AUTOSAR XML (schema 4-2-1)
package /RootP_IntDcm
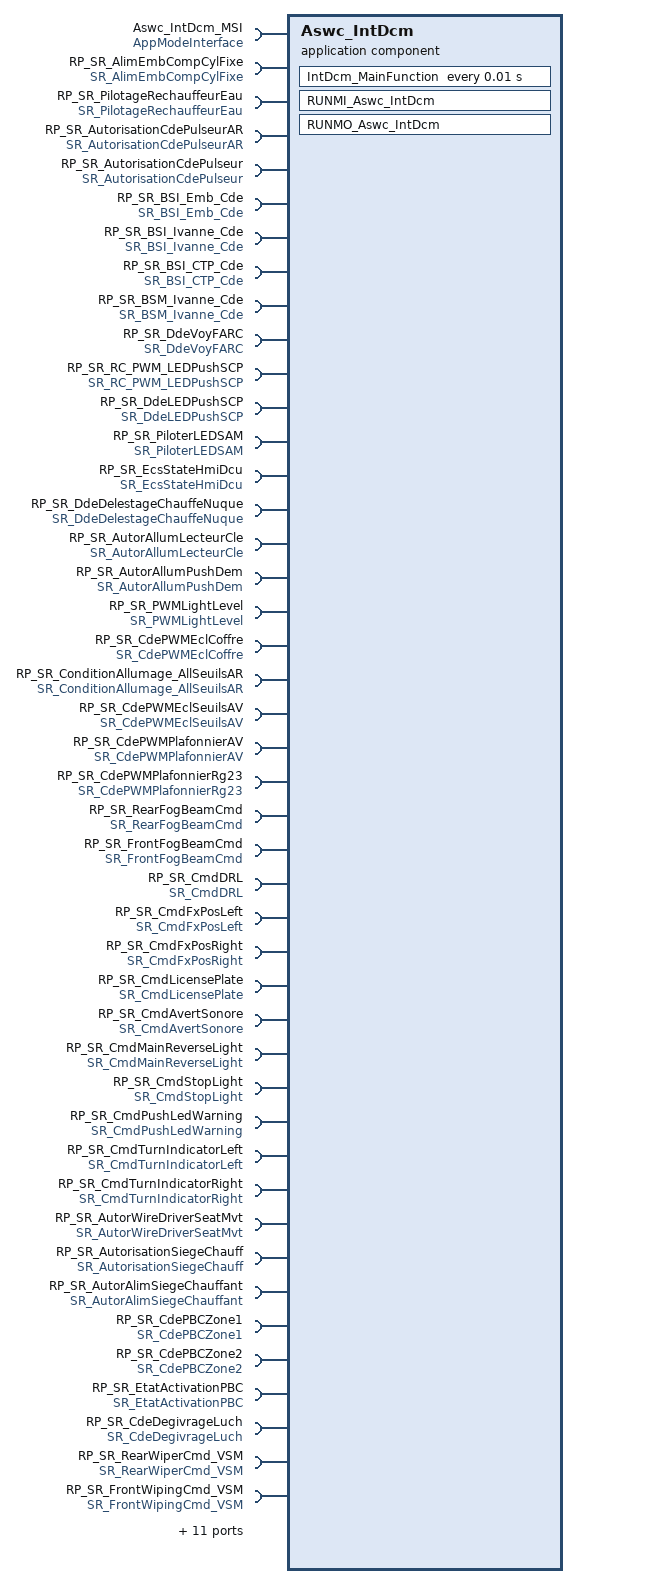
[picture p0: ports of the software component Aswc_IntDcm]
  application sw component type Aswc_IntDcm
    55 x require port:
      Aswc_IntDcm_MSI: required-interface=AppModeInterface
      RP_SR_AlimEmbCompCylFixe: nonqueued-receiver-com-spec{data-element=AlimEmbCompCylFixe, enable-update=0, handle-data-status=0, handle-never-received=0, init-value=CONST_AlimEmbCompCylFixe_0:0}, required-interface=SR_AlimEmbCompCylFixe
      RP_SR_PilotageRechauffeurEau: nonqueued-receiver-com-spec{data-element=PilotageRechauffeurEau, enable-update=0, handle-data-status=0, handle-never-received=0, init-value=CONST_PilotageRechauffeurEau_0:0}, required-interface=SR_PilotageRechauffeurEau
      RP_SR_AutorisationCdePulseurAR: nonqueued-receiver-com-spec{data-element=AutorisationCdePulseurAR, enable-update=0, handle-data-status=0, handle-never-received=0, init-value=CONST_AutorisationCdePulseurAR_0:0}, required-interface=SR_AutorisationCdePulseurAR
      RP_SR_AutorisationCdePulseur: nonqueued-receiver-com-spec{data-element=AutorisationCdePulseur, enable-update=0, handle-data-status=0, handle-never-received=0, init-value=CONST_AutorisationCdePulseur_0:0}, required-interface=SR_AutorisationCdePulseur
      RP_SR_BSI_Emb_Cde: nonqueued-receiver-com-spec{data-element=BSI_Emb_Cde, enable-update=0, handle-data-status=0, handle-never-received=0, init-value=CONST_BSI_Emb_Cde_0:0}, required-interface=SR_BSI_Emb_Cde
      RP_SR_BSI_Ivanne_Cde: nonqueued-receiver-com-spec{data-element=BSI_Ivanne_Cde, enable-update=0, handle-data-status=0, handle-never-received=0, init-value=CONST_BSI_Ivanne_Cde_0:0}, required-interface=SR_BSI_Ivanne_Cde
      RP_SR_BSI_CTP_Cde: nonqueued-receiver-com-spec{data-element=BSI_CTP_Cde, enable-update=0, handle-data-status=0, handle-never-received=0, init-value=CONST_BSI_CTP_Cde_0:0}, required-interface=SR_BSI_CTP_Cde
      RP_SR_BSM_Ivanne_Cde: nonqueued-receiver-com-spec{data-element=BSM_Ivanne_Cde, enable-update=0, handle-data-status=0, handle-never-received=0, init-value=CONST_BSM_Ivanne_Cde_0:0}, required-interface=SR_BSM_Ivanne_Cde
      RP_SR_DdeVoyFARC: nonqueued-receiver-com-spec{data-element=DdeVoyFARC, enable-update=0, handle-data-status=0, handle-never-received=0, init-value=CONST_DdeVoyFARC_0:0}, required-interface=SR_DdeVoyFARC
      RP_SR_RC_PWM_LEDPushSCP: nonqueued-receiver-com-spec{data-element=RC_PWM_LEDPushSCP, enable-update=0, handle-data-status=0, handle-never-received=0, init-value=CONST_RC_PWM_LEDPushSCP_0:0}, required-interface=SR_RC_PWM_LEDPushSCP
      RP_SR_DdeLEDPushSCP: nonqueued-receiver-com-spec{data-element=DdeLEDPushSCP, enable-update=0, handle-data-status=0, handle-never-received=0, init-value=CONST_DdeLEDPushSCP_0:0}, required-interface=SR_DdeLEDPushSCP
      RP_SR_PiloterLEDSAM: nonqueued-receiver-com-spec{data-element=PiloterLEDSAM, enable-update=0, handle-data-status=0, handle-never-received=0, init-value=CONST_PiloterLEDSAM_0:0}, required-interface=SR_PiloterLEDSAM
      RP_SR_EcsStateHmiDcu: nonqueued-receiver-com-spec{data-element=EcsStateHmiDcu, enable-update=0, handle-data-status=0, handle-never-received=0, init-value=CONST_EcsStateHmiDcu_0:0}, required-interface=SR_EcsStateHmiDcu
      RP_SR_DdeDelestageChauffeNuque: nonqueued-receiver-com-spec{data-element=DdeDelestageChauffeNuque, enable-update=0, handle-data-status=0, handle-never-received=0, init-value=CONST_DdeDelestageChauffeNuque_0:0}, required-interface=SR_DdeDelestageChauffeNuque
      RP_SR_AutorAllumLecteurCle: nonqueued-receiver-com-spec{data-element=AutorAllumLecteurCle, enable-update=0, handle-data-status=0, handle-never-received=0, init-value=CONST_AutorAllumLecteurCle_0:0}, required-interface=SR_AutorAllumLecteurCle
      RP_SR_AutorAllumPushDem: nonqueued-receiver-com-spec{data-element=AutorAllumPushDem, enable-update=0, handle-data-status=0, handle-never-received=0, init-value=CONST_AutorAllumPushDem_0:0}, required-interface=SR_AutorAllumPushDem
      RP_SR_PWMLightLevel: nonqueued-receiver-com-spec{data-element=PWMLightLevel, enable-update=0, handle-data-status=0, handle-never-received=0, init-value=CONST_PWMLightLevel_0:0}, required-interface=SR_PWMLightLevel
      RP_SR_CdePWMEclCoffre: nonqueued-receiver-com-spec{data-element=CdePWMEclCoffre, enable-update=0, handle-data-status=0, handle-never-received=0, init-value=CONST_CdePWMEclCoffre_0:0}, required-interface=SR_CdePWMEclCoffre
      RP_SR_ConditionAllumage_AllSeuilsAR: nonqueued-receiver-com-spec{data-element=ConditionAllumage_AllSeuilsAR, enable-update=0, handle-data-status=0, handle-never-received=0, init-value=CONST_ConditionAllumage_AllSeuilsAR_0:0}, required-interface=SR_ConditionAllumage_AllSeuilsAR
      RP_SR_CdePWMEclSeuilsAV: nonqueued-receiver-com-spec{data-element=CdePWMEclSeuilsAV, enable-update=0, handle-data-status=0, handle-never-received=0, init-value=CONST_CdePWMEclSeuilsAV_0:0}, required-interface=SR_CdePWMEclSeuilsAV
      RP_SR_CdePWMPlafonnierAV: nonqueued-receiver-com-spec{data-element=CdePWMPlafonnierAV, enable-update=0, handle-data-status=0, handle-never-received=0, init-value=CONST_CdePWMPlafonnierAV_0:0}, required-interface=SR_CdePWMPlafonnierAV
      RP_SR_CdePWMPlafonnierRg23: nonqueued-receiver-com-spec{data-element=CdePWMPlafonnierRg23, enable-update=0, handle-data-status=0, handle-never-received=0, init-value=CONST_CdePWMPlafonnierRg23_0:0}, required-interface=SR_CdePWMPlafonnierRg23
      RP_SR_RearFogBeamCmd: nonqueued-receiver-com-spec{data-element=RearFogBeamCmd, enable-update=0, handle-data-status=0, handle-never-received=0, init-value=CONST_RearFogBeamCmd_0:0}, required-interface=SR_RearFogBeamCmd
      RP_SR_FrontFogBeamCmd: nonqueued-receiver-com-spec{data-element=FrontFogBeamCmd, enable-update=0, handle-data-status=0, handle-never-received=0, init-value=CONST_FrontFogBeamCmd_0:0}, required-interface=SR_FrontFogBeamCmd
      RP_SR_CmdDRL: nonqueued-receiver-com-spec{data-element=CmdDRL, enable-update=0, handle-data-status=0, handle-never-received=0, init-value=CONST_CmdDRL_0:0}, required-interface=SR_CmdDRL
      RP_SR_CmdFxPosLeft: nonqueued-receiver-com-spec{data-element=CmdFxPosLeft, enable-update=0, handle-data-status=0, handle-never-received=0, init-value=CONST_CmdFxPosLeft_0:0}, required-interface=SR_CmdFxPosLeft
      RP_SR_CmdFxPosRight: nonqueued-receiver-com-spec{data-element=CmdFxPosRight, enable-update=0, handle-data-status=0, handle-never-received=0, init-value=CONST_CmdFxPosRight_0:0}, required-interface=SR_CmdFxPosRight
      RP_SR_CmdLicensePlate: nonqueued-receiver-com-spec{data-element=CmdLicensePlate, enable-update=0, handle-data-status=0, handle-never-received=0, init-value=CONST_CmdLicensePlate_0:0}, required-interface=SR_CmdLicensePlate
      RP_SR_CmdAvertSonore: nonqueued-receiver-com-spec{data-element=CmdAvertSonore, enable-update=0, handle-data-status=0, handle-never-received=0, init-value=CONST_CmdAvertSonore_0:0}, required-interface=SR_CmdAvertSonore
      RP_SR_CmdMainReverseLight: nonqueued-receiver-com-spec{data-element=CmdMainReverseLight, enable-update=0, handle-data-status=0, handle-never-received=0, init-value=CONST_CmdMainReverseLight_0:0}, required-interface=SR_CmdMainReverseLight
      RP_SR_CmdStopLight: nonqueued-receiver-com-spec{data-element=CmdStopLight, enable-update=0, handle-data-status=0, handle-never-received=0, init-value=CONST_CmdStopLight_0:0}, required-interface=SR_CmdStopLight
      RP_SR_CmdPushLedWarning: nonqueued-receiver-com-spec{data-element=CmdPushLedWarning, enable-update=0, handle-data-status=0, handle-never-received=0, init-value=CONST_CmdPushLedWarning_0:0}, required-interface=SR_CmdPushLedWarning
      RP_SR_CmdTurnIndicatorLeft: nonqueued-receiver-com-spec{data-element=CmdTurnIndicatorLeft, enable-update=0, handle-data-status=0, handle-never-received=0, init-value=CONST_CmdTurnIndicatorLeft_0:0}, required-interface=SR_CmdTurnIndicatorLeft
      RP_SR_CmdTurnIndicatorRight: nonqueued-receiver-com-spec{data-element=CmdTurnIndicatorRight, enable-update=0, handle-data-status=0, handle-never-received=0, init-value=CONST_CmdTurnIndicatorRight_0:0}, required-interface=SR_CmdTurnIndicatorRight
      RP_SR_AutorWireDriverSeatMvt: nonqueued-receiver-com-spec{data-element=AutorWireDriverSeatMvt, enable-update=0, handle-data-status=0, handle-never-received=0, init-value=CONST_AutorWireDriverSeatMvt_0:0}, required-interface=SR_AutorWireDriverSeatMvt
      RP_SR_AutorisationSiegeChauff: nonqueued-receiver-com-spec{data-element=AutorisationSiegeChauff, enable-update=0, handle-data-status=0, handle-never-received=0, init-value=CONST_AutorisationSiegeChauff_0:0}, required-interface=SR_AutorisationSiegeChauff
      RP_SR_AutorAlimSiegeChauffant: nonqueued-receiver-com-spec{data-element=AutorAlimSiegeChauffant, enable-update=0, handle-data-status=0, handle-never-received=0, init-value=CONST_AutorAlimSiegeChauffant_0:0}, required-interface=SR_AutorAlimSiegeChauffant
      RP_SR_CdePBCZone1: nonqueued-receiver-com-spec{data-element=CdePBCZone1, enable-update=0, handle-data-status=0, handle-never-received=0, init-value=CONST_CdePBCZone1_0:0}, required-interface=SR_CdePBCZone1
      RP_SR_CdePBCZone2: nonqueued-receiver-com-spec{data-element=CdePBCZone2, enable-update=0, handle-data-status=0, handle-never-received=0, init-value=CONST_CdePBCZone2_0:0}, required-interface=SR_CdePBCZone2
      RP_SR_EtatActivationPBC: nonqueued-receiver-com-spec{data-element=EtatActivationPBC, enable-update=0, handle-data-status=0, handle-never-received=0, init-value=CONST_EtatActivationPBC_0:0}, required-interface=SR_EtatActivationPBC
      RP_SR_CdeDegivrageLuch: nonqueued-receiver-com-spec{data-element=CdeDegivrageLuch, enable-update=0, handle-data-status=0, handle-never-received=0, init-value=CONST_CdeDegivrageLuch_0:0}, required-interface=SR_CdeDegivrageLuch
      RP_SR_RearWiperCmd_VSM: nonqueued-receiver-com-spec{data-element=RearWipingCommand, enable-update=0, handle-data-status=0, handle-never-received=0, init-value=CONST_RearWipingCommand_0:105}, required-interface=SR_RearWiperCmd_VSM
      RP_SR_FrontWipingCmd_VSM: nonqueued-receiver-com-spec{data-element=FrontWipingCommand, enable-update=0, handle-data-status=0, handle-never-received=0, init-value=CONST_FrontWipingCommand_0:105}, required-interface=SR_FrontWipingCmd_VSM
      RP_SR_RearWashingCmd_VSM: nonqueued-receiver-com-spec{data-element=RearWashingCommand, enable-update=0, handle-data-status=0, handle-never-received=0, init-value=CONST_RearWashingCommand_0:0}, required-interface=SR_RearWashingCmd_VSM
      RP_SR_FrontWashingCmd_VSM: nonqueued-receiver-com-spec{data-element=FrontWashingCommand, enable-update=0, handle-data-status=0, handle-never-received=0, init-value=CONST_FrontWashingCommand_0:0}, required-interface=SR_FrontWashingCmd_VSM
      RP_SR_AffMenuEclAmbi: nonqueued-receiver-com-spec{data-element=AffMenuEclAmbi, enable-update=0, handle-data-status=0, handle-never-received=0, init-value=CONST_AffMenuEclAmbi_0:0}, required-interface=SR_AffMenuEclAmbi
      RP_SR_CdeAlerteSonoreKlaxon: nonqueued-receiver-com-spec{data-element=CdeAlerteSonoreKlaxon, enable-update=0, handle-data-status=0, handle-never-received=0, init-value=CONST_CdeAlerteSonoreKlaxon_0:0}, required-interface=SR_CdeAlerteSonoreKlaxon
      RP_SR_CmdActivationSurvAS: nonqueued-receiver-com-spec{data-element=CmdActivationSurvAS, enable-update=0, handle-data-status=0, handle-never-received=0, init-value=CONST_CmdActivationSurvAS_0:4}, required-interface=SR_CmdActivationSurvAS
      RP_SR_CmdActivationSurvSIR: nonqueued-receiver-com-spec{data-element=CmdActivationSurvSIR, enable-update=0, handle-data-status=0, handle-never-received=0, init-value=CONST_CmdActivationSurvSIR_0:0}, required-interface=SR_CmdActivationSurvSIR
      RP_SR_CmdActivationSurvVOL: nonqueued-receiver-com-spec{data-element=CmdActivationSurvVOL, enable-update=0, handle-data-status=0, handle-never-received=0, init-value=CONST_CmdActivationSurvVOL_0:4}, required-interface=SR_CmdActivationSurvVOL
      RP_SR_DdeSignalEffractionInterne: nonqueued-receiver-com-spec{data-element=DdeSignalEffractionInterne, enable-update=0, handle-data-status=0, handle-never-received=0, init-value=CONST_DdeSignalEffractionInterne_0:0}, required-interface=SR_DdeSignalEffractionInterne
      RP_SR_SAV_RC_LEDPushAlarme: nonqueued-receiver-com-spec{data-element=SAV_RC_LEDPushAlarme, enable-update=0, handle-data-status=0, handle-never-received=0, init-value=CONST_SAV_RC_LEDPushAlarme_0:0}, required-interface=SR_SAV_RC_LEDPushAlarme
      RP_SR_SignalActivAlarmeInterne: nonqueued-receiver-com-spec{data-element=SignalActivAlarmeInterne, enable-update=0, handle-data-status=0, handle-never-received=0, init-value=CONST_SignalActivAlarmeInterne_0:0}, required-interface=SR_SignalActivAlarmeInterne
      RP_SR_SignalDesactivAlarmeInterne: nonqueued-receiver-com-spec{data-element=SignalDesactivAlarmeInterne, enable-update=0, handle-data-status=0, handle-never-received=0, init-value=CONST_SignalDesactivAlarmeInterne_0:0}, required-interface=SR_SignalDesactivAlarmeInterne
    54 x provide/require port:
      PRP_SR_AlimEmbCompCylFixe_IoFromDcm: nonqueued-receiver-com-spec{data-element=AlimEmbCompCylFixe, enable-update=0, handle-data-status=0, handle-never-received=0, init-value=CONST_AlimEmbCompCylFixe_0:0}, provided-required-interface=SR_AlimEmbCompCylFixe_IoFromDcm
      PRP_SR_PilotageRechauffeurEau_IoFromDcm: nonqueued-receiver-com-spec{data-element=PilotageRechauffeurEau, enable-update=0, handle-data-status=0, handle-never-received=0, init-value=CONST_PilotageRechauffeurEau_0:0}, provided-required-interface=SR_PilotageRechauffeurEau_IoFromDcm
      PRP_SR_AutorisationCdePulseurAR_IoFromDcm: nonqueued-receiver-com-spec{data-element=AutorisationCdePulseurAR, enable-update=0, handle-data-status=0, handle-never-received=0, init-value=CONST_AutorisationCdePulseurAR_0:0}, provided-required-interface=SR_AutorisationCdePulseurAR_IoFromDcm
      PRP_SR_AutorisationCdePulseur_IoFromDcm: nonqueued-receiver-com-spec{data-element=AutorisationCdePulseur, enable-update=0, handle-data-status=0, handle-never-received=0, init-value=CONST_AutorisationCdePulseur_0:0}, provided-required-interface=SR_AutorisationCdePulseur_IoFromDcm
      PRP_SR_BSI_Emb_Cde_IoFromDcm: nonqueued-receiver-com-spec{data-element=BSI_Emb_Cde, enable-update=0, handle-data-status=0, handle-never-received=0, init-value=CONST_BSI_Emb_Cde_0:0}, provided-required-interface=SR_BSI_Emb_Cde_IoFromDcm
      PRP_SR_BSI_Ivanne_Cde_IoFromDcm: nonqueued-receiver-com-spec{data-element=BSI_Ivanne_Cde, enable-update=0, handle-data-status=0, handle-never-received=0, init-value=CONST_BSI_Ivanne_Cde_0:0}, provided-required-interface=SR_BSI_Ivanne_Cde_IoFromDcm
      PRP_SR_BSI_CTP_Cde_IoFromDcm: nonqueued-receiver-com-spec{data-element=BSI_CTP_Cde, enable-update=0, handle-data-status=0, handle-never-received=0, init-value=CONST_BSI_CTP_Cde_0:0}, provided-required-interface=SR_BSI_CTP_Cde_IoFromDcm
      PRP_SR_BSM_Ivanne_Cde_IoFromDcm: nonqueued-receiver-com-spec{data-element=BSM_Ivanne_Cde, enable-update=0, handle-data-status=0, handle-never-received=0, init-value=CONST_BSM_Ivanne_Cde_0:0}, provided-required-interface=SR_BSM_Ivanne_Cde_IoFromDcm
      PRP_SR_DdeVoyFARC_IoFromDcm: nonqueued-receiver-com-spec{data-element=DdeVoyFARC, enable-update=0, handle-data-status=0, handle-never-received=0, init-value=CONST_DdeVoyFARC_0:0}, provided-required-interface=SR_DdeVoyFARC_IoFromDcm
      PRP_SR_RC_PWM_LEDPushSCP_IoFromDcm: nonqueued-receiver-com-spec{data-element=RC_PWM_LEDPushSCP, enable-update=0, handle-data-status=0, handle-never-received=0, init-value=CONST_RC_PWM_LEDPushSCP_0:0}, provided-required-interface=SR_RC_PWM_LEDPushSCP_IoFromDcm
      PRP_SR_DdeLEDPushSCP_IoFromDcm: nonqueued-receiver-com-spec{data-element=DdeLEDPushSCP, enable-update=0, handle-data-status=0, handle-never-received=0, init-value=CONST_DdeLEDPushSCP_0:0}, provided-required-interface=SR_DdeLEDPushSCP_IoFromDcm
      PRP_SR_PiloterLEDSAM_IoFromDcm: nonqueued-receiver-com-spec{data-element=PiloterLEDSAM, enable-update=0, handle-data-status=0, handle-never-received=0, init-value=CONST_PiloterLEDSAM_0:0}, provided-required-interface=SR_PiloterLEDSAM_IoFromDcm
      PRP_SR_EcsStateHmiDcu_IoFromDcm: nonqueued-receiver-com-spec{data-element=EcsStateHmiDcu, enable-update=0, handle-data-status=0, handle-never-received=0, init-value=CONST_EcsStateHmiDcu_0:0}, provided-required-interface=SR_EcsStateHmiDcu_IoFromDcm
      PRP_SR_DdeDelestageChauffeNuque_IoFromDcm: nonqueued-receiver-com-spec{data-element=DdeDelestageChauffeNuque, enable-update=0, handle-data-status=0, handle-never-received=0, init-value=CONST_DdeDelestageChauffeNuque_0:0}, provided-required-interface=SR_DdeDelestageChauffeNuque_IoFromDcm
      PRP_SR_AutorAllumLecteurCle_IoFromDcm: nonqueued-receiver-com-spec{data-element=AutorAllumLecteurCle, enable-update=0, handle-data-status=0, handle-never-received=0, init-value=CONST_AutorAllumLecteurCle_0:0}, provided-required-interface=SR_AutorAllumLecteurCle_IoFromDcm
      PRP_SR_AutorAllumPushDem_IoFromDcm: nonqueued-receiver-com-spec{data-element=AutorAllumPushDem, enable-update=0, handle-data-status=0, handle-never-received=0, init-value=CONST_AutorAllumPushDem_0:0}, provided-required-interface=SR_AutorAllumPushDem_IoFromDcm
      PRP_SR_PWMLightLevel_IoFromDcm: nonqueued-receiver-com-spec{data-element=PWMLightLevel, enable-update=0, handle-data-status=0, handle-never-received=0, init-value=CONST_PWMLightLevel_0:0}, provided-required-interface=SR_PWMLightLevel_IoFromDcm
      PRP_SR_CdePWMEclCoffre_IoFromDcm: nonqueued-receiver-com-spec{data-element=CdePWMEclCoffre, enable-update=0, handle-data-status=0, handle-never-received=0, init-value=CONST_CdePWMEclCoffre_0:0}, provided-required-interface=SR_CdePWMEclCoffre_IoFromDcm
      PRP_SR_ConditionAllumage_AllSeuilsAR_IoFromDcm: nonqueued-receiver-com-spec{data-element=ConditionAllumage_AllSeuilsAR, enable-update=0, handle-data-status=0, handle-never-received=0, init-value=CONST_ConditionAllumage_AllSeuilsAR_0:0}, provided-required-interface=SR_ConditionAllumage_AllSeuilsAR_IoFromDcm
      PRP_SR_CdePWMEclSeuilsAV_IoFromDcm: nonqueued-receiver-com-spec{data-element=CdePWMEclSeuilsAV, enable-update=0, handle-data-status=0, handle-never-received=0, init-value=CONST_CdePWMEclSeuilsAV_0:0}, provided-required-interface=SR_CdePWMEclSeuilsAV_IoFromDcm
      PRP_SR_CdePWMPlafonnierAV_IoFromDcm: nonqueued-receiver-com-spec{data-element=CdePWMPlafonnierAV, enable-update=0, handle-data-status=0, handle-never-received=0, init-value=CONST_CdePWMPlafonnierAV_0:0}, provided-required-interface=SR_CdePWMPlafonnierAV_IoFromDcm
      PRP_SR_CdePWMPlafonnierRg23_IoFromDcm: nonqueued-receiver-com-spec{data-element=CdePWMPlafonnierRg23, enable-update=0, handle-data-status=0, handle-never-received=0, init-value=CONST_CdePWMPlafonnierRg23_0:0}, provided-required-interface=SR_CdePWMPlafonnierRg23_IoFromDcm
      PRP_SR_RearFogBeamCmd_IoFromDcm: nonqueued-receiver-com-spec{data-element=RearFogBeamCmd, enable-update=0, handle-data-status=0, handle-never-received=0, init-value=CONST_RearFogBeamCmd_0:0}, provided-required-interface=SR_RearFogBeamCmd_IoFromDcm
      PRP_SR_FrontFogBeamCmd_IoFromDcm: nonqueued-receiver-com-spec{data-element=FrontFogBeamCmd, enable-update=0, handle-data-status=0, handle-never-received=0, init-value=CONST_FrontFogBeamCmd_0:0}, provided-required-interface=SR_FrontFogBeamCmd_IoFromDcm
      PRP_SR_CmdDRL_IoFromDcm: nonqueued-receiver-com-spec{data-element=CmdDRL, enable-update=0, handle-data-status=0, handle-never-received=0, init-value=CONST_CmdDRL_0:0}, provided-required-interface=SR_CmdDRL_IoFromDcm
      PRP_SR_CmdFxPosLeft_IoFromDcm: nonqueued-receiver-com-spec{data-element=CmdFxPosLeft, enable-update=0, handle-data-status=0, handle-never-received=0, init-value=CONST_CmdFxPosLeft_0:0}, provided-required-interface=SR_CmdFxPosLeft_IoFromDcm
      PRP_SR_CmdFxPosRight_IoFromDcm: nonqueued-receiver-com-spec{data-element=CmdFxPosRight, enable-update=0, handle-data-status=0, handle-never-received=0, init-value=CONST_CmdFxPosRight_0:0}, provided-required-interface=SR_CmdFxPosRight_IoFromDcm
      PRP_SR_CmdLicensePlate_IoFromDcm: nonqueued-receiver-com-spec{data-element=CmdLicensePlate, enable-update=0, handle-data-status=0, handle-never-received=0, init-value=CONST_CmdLicensePlate_0:0}, provided-required-interface=SR_CmdLicensePlate_IoFromDcm
      PRP_SR_CmdAvertSonore_IoFromDcm: nonqueued-receiver-com-spec{data-element=CmdAvertSonore, enable-update=0, handle-data-status=0, handle-never-received=0, init-value=CONST_CmdAvertSonore_0:0}, provided-required-interface=SR_CmdAvertSonore_IoFromDcm
      PRP_SR_CmdMainReverseLight_IoFromDcm: nonqueued-receiver-com-spec{data-element=CmdMainReverseLight, enable-update=0, handle-data-status=0, handle-never-received=0, init-value=CONST_CmdMainReverseLight_0:0}, provided-required-interface=SR_CmdMainReverseLight_IoFromDcm
      PRP_SR_CmdStopLight_IoFromDcm: nonqueued-receiver-com-spec{data-element=CmdStopLight, enable-update=0, handle-data-status=0, handle-never-received=0, init-value=CONST_CmdStopLight_0:0}, provided-required-interface=SR_CmdStopLight_IoFromDcm
      PRP_SR_CmdPushLedWarning_IoFromDcm: nonqueued-receiver-com-spec{data-element=CmdPushLedWarning, enable-update=0, handle-data-status=0, handle-never-received=0, init-value=CONST_CmdPushLedWarning_0:0}, provided-required-interface=SR_CmdPushLedWarning_IoFromDcm
      PRP_SR_CmdTurnIndicatorLeft_IoFromDcm: nonqueued-receiver-com-spec{data-element=CmdTurnIndicatorLeft, enable-update=0, handle-data-status=0, handle-never-received=0, init-value=CONST_CmdTurnIndicatorLeft_0:0}, provided-required-interface=SR_CmdTurnIndicatorLeft_IoFromDcm
      PRP_SR_CmdTurnIndicatorRight_IoFromDcm: nonqueued-receiver-com-spec{data-element=CmdTurnIndicatorRight, enable-update=0, handle-data-status=0, handle-never-received=0, init-value=CONST_CmdTurnIndicatorRight_0:0}, provided-required-interface=SR_CmdTurnIndicatorRight_IoFromDcm
      PRP_SR_AutorWireDriverSeatMvt_IoFromDcm: nonqueued-receiver-com-spec{data-element=AutorWireDriverSeatMvt, enable-update=0, handle-data-status=0, handle-never-received=0, init-value=CONST_AutorWireDriverSeatMvt_0:0}, provided-required-interface=SR_AutorWireDriverSeatMvt_IoFromDcm
      PRP_SR_AutorisationSiegeChauff_IoFromDcm: nonqueued-receiver-com-spec{data-element=AutorisationSiegeChauff, enable-update=0, handle-data-status=0, handle-never-received=0, init-value=CONST_AutorisationSiegeChauff_0:0}, provided-required-interface=SR_AutorisationSiegeChauff_IoFromDcm
      PRP_SR_AutorAlimSiegeChauffant_IoFromDcm: nonqueued-receiver-com-spec{data-element=AutorAlimSiegeChauffant, enable-update=0, handle-data-status=0, handle-never-received=0, init-value=CONST_AutorAlimSiegeChauffant_0:0}, provided-required-interface=SR_AutorAlimSiegeChauffant_IoFromDcm
      PRP_SR_CdePBCZone1_IoFromDcm: nonqueued-receiver-com-spec{data-element=CdePBCZone1, enable-update=0, handle-data-status=0, handle-never-received=0, init-value=CONST_CdePBCZone1_0:0}, provided-required-interface=SR_CdePBCZone1_IoFromDcm
      PRP_SR_CdePBCZone2_IoFromDcm: nonqueued-receiver-com-spec{data-element=CdePBCZone2, enable-update=0, handle-data-status=0, handle-never-received=0, init-value=CONST_CdePBCZone2_0:0}, provided-required-interface=SR_CdePBCZone2_IoFromDcm
      PRP_SR_EtatActivationPBC_IoFromDcm: nonqueued-receiver-com-spec{data-element=EtatActivationPBC, enable-update=0, handle-data-status=0, handle-never-received=0, init-value=CONST_EtatActivationPBC_0:0}, provided-required-interface=SR_EtatActivationPBC_IoFromDcm
      PRP_SR_CdeDegivrageLuch_IoFromDcm: nonqueued-receiver-com-spec{data-element=CdeDegivrageLuch, enable-update=0, handle-data-status=0, handle-never-received=0, init-value=CONST_CdeDegivrageLuch_0:0}, provided-required-interface=SR_CdeDegivrageLuch_IoFromDcm
      PRP_SR_RearWiperCmd_VSM_IoFromDcm: nonqueued-receiver-com-spec{data-element=RearWipingCommand, enable-update=0, handle-data-status=0, handle-never-received=0, init-value=CONST_RearWipingCommand_0:105}, provided-required-interface=SR_RearWiperCmd_VSM_IoFromDcm
      PRP_SR_FrontWipingCmd_VSM_IoFromDcm: nonqueued-receiver-com-spec{data-element=FrontWipingCommand, enable-update=0, handle-data-status=0, handle-never-received=0, init-value=CONST_FrontWipingCommand_0:105}, provided-required-interface=SR_FrontWipingCmd_VSM_IoFromDcm
      PRP_SR_RearWashingCmd_VSM_IoFromDcm: nonqueued-receiver-com-spec{data-element=RearWashingCommand, enable-update=0, handle-data-status=0, handle-never-received=0, init-value=CONST_RearWashingCommand_0:0}, provided-required-interface=SR_RearWashingCmd_VSM_IoFromDcm
      PRP_SR_FrontWashingCmd_VSM_IoFromDcm: nonqueued-receiver-com-spec{data-element=FrontWashingCommand, enable-update=0, handle-data-status=0, handle-never-received=0, init-value=CONST_FrontWashingCommand_0:0}, provided-required-interface=SR_FrontWashingCmd_VSM_IoFromDcm
      PRP_SR_AffMenuEclAmbi_IoFromDcm: nonqueued-receiver-com-spec{data-element=AffMenuEclAmbi, enable-update=0, handle-data-status=0, handle-never-received=0, init-value=CONST_AffMenuEclAmbi_0:0}, provided-required-interface=SR_AffMenuEclAmbi_IoFromDcm
      PRP_SR_CdeAlerteSonoreKlaxon_IoFromDcm: nonqueued-receiver-com-spec{data-element=CdeAlerteSonoreKlaxon, enable-update=0, handle-data-status=0, handle-never-received=0, init-value=CONST_CdeAlerteSonoreKlaxon_0:0}, provided-required-interface=SR_CdeAlerteSonoreKlaxon_IoFromDcm
      PRP_SR_CmdActivationSurvAS_IoFromDcm: nonqueued-receiver-com-spec{data-element=CmdActivationSurvAS, enable-update=0, handle-data-status=0, handle-never-received=0, init-value=CONST_CmdActivationSurvAS_0:4}, provided-required-interface=SR_CmdActivationSurvAS_IoFromDcm
      PRP_SR_CmdActivationSurvSIR_IoFromDcm: nonqueued-receiver-com-spec{data-element=CmdActivationSurvSIR, enable-update=0, handle-data-status=0, handle-never-received=0, init-value=CONST_CmdActivationSurvSIR_0:0}, provided-required-interface=SR_CmdActivationSurvSIR_IoFromDcm
      PRP_SR_CmdActivationSurvVOL_IoFromDcm: nonqueued-receiver-com-spec{data-element=CmdActivationSurvVOL, enable-update=0, handle-data-status=0, handle-never-received=0, init-value=CONST_CmdActivationSurvVOL_0:4}, provided-required-interface=SR_CmdActivationSurvVOL_IoFromDcm
      PRP_SR_DdeSignalEffractionInterne_IoFromDcm: nonqueued-receiver-com-spec{data-element=DdeSignalEffractionInterne, enable-update=0, handle-data-status=0, handle-never-received=0, init-value=CONST_DdeSignalEffractionInterne_0:0}, provided-required-interface=SR_DdeSignalEffractionInterne_IoFromDcm
      PRP_SR_SAV_RC_LEDPushAlarme_IoFromDcm: nonqueued-receiver-com-spec{data-element=SAV_RC_LEDPushAlarme, enable-update=0, handle-data-status=0, handle-never-received=0, init-value=CONST_SAV_RC_LEDPushAlarme_0:0}, provided-required-interface=SR_SAV_RC_LEDPushAlarme_IoFromDcm
      PRP_SR_SignalActivAlarmeInterne_IoFromDcm: nonqueued-receiver-com-spec{data-element=SignalActivAlarmeInterne, enable-update=0, handle-data-status=0, handle-never-received=0, init-value=CONST_SignalActivAlarmeInterne_0:0}, provided-required-interface=SR_SignalActivAlarmeInterne_IoFromDcm
      PRP_SR_SignalDesactivAlarmeInterne_IoFromDcm: nonqueued-receiver-com-spec{data-element=SignalDesactivAlarmeInterne, enable-update=0, handle-data-status=0, handle-never-received=0, init-value=CONST_SignalDesactivAlarmeInterne_0:0}, provided-required-interface=SR_SignalDesactivAlarmeInterne_IoFromDcm
    behavior IB_Aswc_IntDcm: data-type-mapping=ApplicationModeMapping, handle-termination-and-restart=NO-SUPPORT
      timing event IntDcm_MainFunction_Cyclic: start-on-event=IntDcm_MainFunction, period=0.01
        disabled-mode:
          Aswc_IntDcm_MSI.AppMode.APP_WAKEUP
          Aswc_IntDcm_MSI.AppMode.APP_OFF
          Aswc_IntDcm_MSI.AppMode.APP_SYNC_INIT1
          Aswc_IntDcm_MSI.AppMode.APP_SYNC_INIT2
          Aswc_IntDcm_MSI.AppMode.APP_CONFIG
      swc mode switch event RUNMI_Aswc_IntDcm_NvmIn: start-on-event=RUNMI_Aswc_IntDcm, activation=ON-ENTRY, mode=Aswc_IntDcm_MSI.AppMode.APP_SYNC_INIT1
      swc mode switch event RUNMO_Aswc_IntDcm_NvmOut: start-on-event=RUNMO_Aswc_IntDcm, activation=ON-ENTRY, mode=Aswc_IntDcm_MSI.AppMode.APP_ON
      runnable IntDcm_MainFunction
        data-read-access:
          54 x access:
            Dra_SR_AlimEmbCompCylFixe: accessed-variable=RP_SR_AlimEmbCompCylFixe.AlimEmbCompCylFixe
            Dra_SR_PilotageRechauffeurEau: accessed-variable=RP_SR_PilotageRechauffeurEau.PilotageRechauffeurEau
            Dra_SR_AutorisationCdePulseurAR: accessed-variable=RP_SR_AutorisationCdePulseurAR.AutorisationCdePulseurAR
            Dra_SR_AutorisationCdePulseur: accessed-variable=RP_SR_AutorisationCdePulseur.AutorisationCdePulseur
            Dra_SR_BSI_Emb_Cde: accessed-variable=RP_SR_BSI_Emb_Cde.BSI_Emb_Cde
            Dra_SR_BSI_Ivanne_Cde: accessed-variable=RP_SR_BSI_Ivanne_Cde.BSI_Ivanne_Cde
            Dra_SR_BSI_CTP_Cde: accessed-variable=RP_SR_BSI_CTP_Cde.BSI_CTP_Cde
            Dra_SR_BSM_Ivanne_Cde: accessed-variable=RP_SR_BSM_Ivanne_Cde.BSM_Ivanne_Cde
            Dra_SR_DdeVoyFARC: accessed-variable=RP_SR_DdeVoyFARC.DdeVoyFARC
            Dra_SR_RC_PWM_LEDPushSCP: accessed-variable=RP_SR_RC_PWM_LEDPushSCP.RC_PWM_LEDPushSCP
            Dra_SR_DdeLEDPushSCP: accessed-variable=RP_SR_DdeLEDPushSCP.DdeLEDPushSCP
            Dra_SR_PiloterLEDSAM: accessed-variable=RP_SR_PiloterLEDSAM.PiloterLEDSAM
            Dra_SR_EcsStateHmiDcu: accessed-variable=RP_SR_EcsStateHmiDcu.EcsStateHmiDcu
            Dra_SR_DdeDelestageChauffeNuque: accessed-variable=RP_SR_DdeDelestageChauffeNuque.DdeDelestageChauffeNuque
            Dra_SR_AutorAllumLecteurCle: accessed-variable=RP_SR_AutorAllumLecteurCle.AutorAllumLecteurCle
            Dra_SR_AutorAllumPushDem: accessed-variable=RP_SR_AutorAllumPushDem.AutorAllumPushDem
            Dra_SR_PWMLightLevel: accessed-variable=RP_SR_PWMLightLevel.PWMLightLevel
            Dra_SR_CdePWMEclCoffre: accessed-variable=RP_SR_CdePWMEclCoffre.CdePWMEclCoffre
            Dra_SR_ConditionAllumage_AllSeuilsAR: accessed-variable=RP_SR_ConditionAllumage_AllSeuilsAR.ConditionAllumage_AllSeuilsAR
            Dra_SR_CdePWMEclSeuilsAV: accessed-variable=RP_SR_CdePWMEclSeuilsAV.CdePWMEclSeuilsAV
            Dra_SR_CdePWMPlafonnierAV: accessed-variable=RP_SR_CdePWMPlafonnierAV.CdePWMPlafonnierAV
            Dra_SR_CdePWMPlafonnierRg23: accessed-variable=RP_SR_CdePWMPlafonnierRg23.CdePWMPlafonnierRg23
            Dra_SR_RearFogBeamCmd: accessed-variable=RP_SR_RearFogBeamCmd.RearFogBeamCmd
            Dra_SR_FrontFogBeamCmd: accessed-variable=RP_SR_FrontFogBeamCmd.FrontFogBeamCmd
            Dra_SR_CmdDRL: accessed-variable=RP_SR_CmdDRL.CmdDRL
            Dra_SR_CmdFxPosLeft: accessed-variable=RP_SR_CmdFxPosLeft.CmdFxPosLeft
            Dra_SR_CmdFxPosRight: accessed-variable=RP_SR_CmdFxPosRight.CmdFxPosRight
            Dra_SR_CmdLicensePlate: accessed-variable=RP_SR_CmdLicensePlate.CmdLicensePlate
            Dra_SR_CmdAvertSonore: accessed-variable=RP_SR_CmdAvertSonore.CmdAvertSonore
            Dra_SR_CmdMainReverseLight: accessed-variable=RP_SR_CmdMainReverseLight.CmdMainReverseLight
            Dra_SR_CmdStopLight: accessed-variable=RP_SR_CmdStopLight.CmdStopLight
            Dra_SR_CmdPushLedWarning: accessed-variable=RP_SR_CmdPushLedWarning.CmdPushLedWarning
            Dra_SR_CmdTurnIndicatorLeft: accessed-variable=RP_SR_CmdTurnIndicatorLeft.CmdTurnIndicatorLeft
            Dra_SR_CmdTurnIndicatorRight: accessed-variable=RP_SR_CmdTurnIndicatorRight.CmdTurnIndicatorRight
            Dra_SR_AutorWireDriverSeatMvt: accessed-variable=RP_SR_AutorWireDriverSeatMvt.AutorWireDriverSeatMvt
            Dra_SR_AutorisationSiegeChauff: accessed-variable=RP_SR_AutorisationSiegeChauff.AutorisationSiegeChauff
            Dra_SR_AutorAlimSiegeChauffant: accessed-variable=RP_SR_AutorAlimSiegeChauffant.AutorAlimSiegeChauffant
            Dra_SR_CdePBCZone1: accessed-variable=RP_SR_CdePBCZone1.CdePBCZone1
            Dra_SR_CdePBCZone2: accessed-variable=RP_SR_CdePBCZone2.CdePBCZone2
            Dra_SR_EtatActivationPBC: accessed-variable=RP_SR_EtatActivationPBC.EtatActivationPBC
            Dra_SR_CdeDegivrageLuch: accessed-variable=RP_SR_CdeDegivrageLuch.CdeDegivrageLuch
            Dra_SR_RearWiperCmd_VSM: accessed-variable=RP_SR_RearWiperCmd_VSM.RearWipingCommand
            Dra_SR_FrontWipingCmd_VSM: accessed-variable=RP_SR_FrontWipingCmd_VSM.FrontWipingCommand
            Dra_SR_RearWashingCmd_VSM: accessed-variable=RP_SR_RearWashingCmd_VSM.RearWashingCommand
            Dra_SR_FrontWashingCmd_VSM: accessed-variable=RP_SR_FrontWashingCmd_VSM.FrontWashingCommand
            Dra_SR_AffMenuEclAmbi: accessed-variable=RP_SR_AffMenuEclAmbi.AffMenuEclAmbi
            Dra_SR_CdeAlerteSonoreKlaxon: accessed-variable=RP_SR_CdeAlerteSonoreKlaxon.CdeAlerteSonoreKlaxon
            Dra_SR_CmdActivationSurvAS: accessed-variable=RP_SR_CmdActivationSurvAS.CmdActivationSurvAS
            Dra_SR_CmdActivationSurvSIR: accessed-variable=RP_SR_CmdActivationSurvSIR.CmdActivationSurvSIR
            Dra_SR_CmdActivationSurvVOL: accessed-variable=RP_SR_CmdActivationSurvVOL.CmdActivationSurvVOL
            Dra_SR_DdeSignalEffractionInterne: accessed-variable=RP_SR_DdeSignalEffractionInterne.DdeSignalEffractionInterne
            Dra_SR_SAV_RC_LEDPushAlarme: accessed-variable=RP_SR_SAV_RC_LEDPushAlarme.SAV_RC_LEDPushAlarme
            Dra_SR_SignalActivAlarmeInterne: accessed-variable=RP_SR_SignalActivAlarmeInterne.SignalActivAlarmeInterne
            Dra_SR_SignalDesactivAlarmeInterne: accessed-variable=RP_SR_SignalDesactivAlarmeInterne.SignalDesactivAlarmeInterne
        data-write-access:
          54 x access:
            Dwa_SR_AlimEmbCompCylFixe: accessed-variable=PRP_SR_AlimEmbCompCylFixe_IoFromDcm.AlimEmbCompCylFixe
            Dwa_SR_PilotageRechauffeurEau: accessed-variable=PRP_SR_PilotageRechauffeurEau_IoFromDcm.PilotageRechauffeurEau
            Dwa_SR_AutorisationCdePulseurAR: accessed-variable=PRP_SR_AutorisationCdePulseurAR_IoFromDcm.AutorisationCdePulseurAR
            Dwa_SR_AutorisationCdePulseur: accessed-variable=PRP_SR_AutorisationCdePulseur_IoFromDcm.AutorisationCdePulseur
            Dwa_SR_BSI_Emb_Cde: accessed-variable=PRP_SR_BSI_Emb_Cde_IoFromDcm.BSI_Emb_Cde
            Dwa_SR_BSI_Ivanne_Cde: accessed-variable=PRP_SR_BSI_Ivanne_Cde_IoFromDcm.BSI_Ivanne_Cde
            Dwa_SR_BSI_CTP_Cde: accessed-variable=PRP_SR_BSI_CTP_Cde_IoFromDcm.BSI_CTP_Cde
            Dwa_SR_BSM_Ivanne_Cde: accessed-variable=PRP_SR_BSM_Ivanne_Cde_IoFromDcm.BSM_Ivanne_Cde
            Dwa_SR_DdeVoyFARC: accessed-variable=PRP_SR_DdeVoyFARC_IoFromDcm.DdeVoyFARC
            Dwa_SR_RC_PWM_LEDPushSCP: accessed-variable=PRP_SR_RC_PWM_LEDPushSCP_IoFromDcm.RC_PWM_LEDPushSCP
            Dwa_SR_DdeLEDPushSCP: accessed-variable=PRP_SR_DdeLEDPushSCP_IoFromDcm.DdeLEDPushSCP
            Dwa_SR_PiloterLEDSAM: accessed-variable=PRP_SR_PiloterLEDSAM_IoFromDcm.PiloterLEDSAM
            Dwa_SR_EcsStateHmiDcu: accessed-variable=PRP_SR_EcsStateHmiDcu_IoFromDcm.EcsStateHmiDcu
            Dwa_SR_DdeDelestageChauffeNuque: accessed-variable=PRP_SR_DdeDelestageChauffeNuque_IoFromDcm.DdeDelestageChauffeNuque
            Dwa_SR_AutorAllumLecteurCle: accessed-variable=PRP_SR_AutorAllumLecteurCle_IoFromDcm.AutorAllumLecteurCle
            Dwa_SR_AutorAllumPushDem: accessed-variable=PRP_SR_AutorAllumPushDem_IoFromDcm.AutorAllumPushDem
            Dwa_SR_PWMLightLevel: accessed-variable=PRP_SR_PWMLightLevel_IoFromDcm.PWMLightLevel
            Dwa_SR_CdePWMEclCoffre: accessed-variable=PRP_SR_CdePWMEclCoffre_IoFromDcm.CdePWMEclCoffre
            Dwa_SR_ConditionAllumage_AllSeuilsAR: accessed-variable=PRP_SR_ConditionAllumage_AllSeuilsAR_IoFromDcm.ConditionAllumage_AllSeuilsAR
            Dwa_SR_CdePWMEclSeuilsAV: accessed-variable=PRP_SR_CdePWMEclSeuilsAV_IoFromDcm.CdePWMEclSeuilsAV
            Dwa_SR_CdePWMPlafonnierAV: accessed-variable=PRP_SR_CdePWMPlafonnierAV_IoFromDcm.CdePWMPlafonnierAV
            Dwa_SR_CdePWMPlafonnierRg23: accessed-variable=PRP_SR_CdePWMPlafonnierRg23_IoFromDcm.CdePWMPlafonnierRg23
            Dwa_SR_RearFogBeamCmd: accessed-variable=PRP_SR_RearFogBeamCmd_IoFromDcm.RearFogBeamCmd
            Dwa_SR_FrontFogBeamCmd: accessed-variable=PRP_SR_FrontFogBeamCmd_IoFromDcm.FrontFogBeamCmd
            Dwa_SR_CmdDRL: accessed-variable=PRP_SR_CmdDRL_IoFromDcm.CmdDRL
            Dwa_SR_CmdFxPosLeft: accessed-variable=PRP_SR_CmdFxPosLeft_IoFromDcm.CmdFxPosLeft
            Dwa_SR_CmdFxPosRight: accessed-variable=PRP_SR_CmdFxPosRight_IoFromDcm.CmdFxPosRight
            Dwa_SR_CmdLicensePlate: accessed-variable=PRP_SR_CmdLicensePlate_IoFromDcm.CmdLicensePlate
            Dwa_SR_CmdAvertSonore: accessed-variable=PRP_SR_CmdAvertSonore_IoFromDcm.CmdAvertSonore
            Dwa_SR_CmdMainReverseLight: accessed-variable=PRP_SR_CmdMainReverseLight_IoFromDcm.CmdMainReverseLight
            Dwa_SR_CmdStopLight: accessed-variable=PRP_SR_CmdStopLight_IoFromDcm.CmdStopLight
            Dwa_SR_CmdPushLedWarning: accessed-variable=PRP_SR_CmdPushLedWarning_IoFromDcm.CmdPushLedWarning
            Dwa_SR_CmdTurnIndicatorLeft: accessed-variable=PRP_SR_CmdTurnIndicatorLeft_IoFromDcm.CmdTurnIndicatorLeft
            Dwa_SR_CmdTurnIndicatorRight: accessed-variable=PRP_SR_CmdTurnIndicatorRight_IoFromDcm.CmdTurnIndicatorRight
            Dwa_SR_AutorWireDriverSeatMvt: accessed-variable=PRP_SR_AutorWireDriverSeatMvt_IoFromDcm.AutorWireDriverSeatMvt
            Dwa_SR_AutorisationSiegeChauff: accessed-variable=PRP_SR_AutorisationSiegeChauff_IoFromDcm.AutorisationSiegeChauff
            Dwa_SR_AutorAlimSiegeChauffant: accessed-variable=PRP_SR_AutorAlimSiegeChauffant_IoFromDcm.AutorAlimSiegeChauffant
            Dwa_SR_CdePBCZone1: accessed-variable=PRP_SR_CdePBCZone1_IoFromDcm.CdePBCZone1
            Dwa_SR_CdePBCZone2: accessed-variable=PRP_SR_CdePBCZone2_IoFromDcm.CdePBCZone2
            Dwa_SR_EtatActivationPBC: accessed-variable=PRP_SR_EtatActivationPBC_IoFromDcm.EtatActivationPBC
            Dwa_SR_CdeDegivrageLuch: accessed-variable=PRP_SR_CdeDegivrageLuch_IoFromDcm.CdeDegivrageLuch
            Dwa_SR_RearWiperCmd_VSM: accessed-variable=PRP_SR_RearWiperCmd_VSM_IoFromDcm.RearWipingCommand
            Dwa_SR_FrontWipingCmd_VSM: accessed-variable=PRP_SR_FrontWipingCmd_VSM_IoFromDcm.FrontWipingCommand
            Dwa_SR_RearWashingCmd_VSM: accessed-variable=PRP_SR_RearWashingCmd_VSM_IoFromDcm.RearWashingCommand
            Dwa_SR_FrontWashingCmd_VSM: accessed-variable=PRP_SR_FrontWashingCmd_VSM_IoFromDcm.FrontWashingCommand
            Dwa_SR_AffMenuEclAmbi: accessed-variable=PRP_SR_AffMenuEclAmbi_IoFromDcm.AffMenuEclAmbi
            Dwa_SR_CdeAlerteSonoreKlaxon: accessed-variable=PRP_SR_CdeAlerteSonoreKlaxon_IoFromDcm.CdeAlerteSonoreKlaxon
            Dwa_SR_CmdActivationSurvAS: accessed-variable=PRP_SR_CmdActivationSurvAS_IoFromDcm.CmdActivationSurvAS
            Dwa_SR_CmdActivationSurvSIR: accessed-variable=PRP_SR_CmdActivationSurvSIR_IoFromDcm.CmdActivationSurvSIR
            Dwa_SR_CmdActivationSurvVOL: accessed-variable=PRP_SR_CmdActivationSurvVOL_IoFromDcm.CmdActivationSurvVOL
            Dwa_SR_DdeSignalEffractionInterne: accessed-variable=PRP_SR_DdeSignalEffractionInterne_IoFromDcm.DdeSignalEffractionInterne
            Dwa_SR_SAV_RC_LEDPushAlarme: accessed-variable=PRP_SR_SAV_RC_LEDPushAlarme_IoFromDcm.SAV_RC_LEDPushAlarme
            Dwa_SR_SignalActivAlarmeInterne: accessed-variable=PRP_SR_SignalActivAlarmeInterne_IoFromDcm.SignalActivAlarmeInterne
            Dwa_SR_SignalDesactivAlarmeInterne: accessed-variable=PRP_SR_SignalDesactivAlarmeInterne_IoFromDcm.SignalDesactivAlarmeInterne
      runnable RUNMI_Aswc_IntDcm
        data-write-access:
          253 x access:
            Dwa_SR_CFG_DEF_VEHICULE_CFG_DEF_VEHICULE: accessed-variable=PRP_SR_CFG_DEF_VEHICULE.CFG_DEF_VEHICULE
            Dwa_SR_CFG_PRESENCE_ETSR_CFG_PRESENCE_ETSR: accessed-variable=PRP_SR_CFG_PRESENCE_ETSR.CFG_PRESENCE_ETSR
            Dwa_SR_CFG_NAV_POI_RADAR_CFG_NAV_POI_RADAR: accessed-variable=PRP_SR_CFG_NAV_POI_RADAR.CFG_NAV_POI_RADAR
            Dwa_SR_CFG_OPT_ANTICIPATED_PLV_CFG_OPT_ANTICIPATED_PLV: accessed-variable=PRP_SR_CFG_OPT_ANTICIPATED_PLV.CFG_OPT_ANTICIPATED_PLV
            Dwa_SR_CFG_TYPE_ILV_CFG_TYPE_ILV: accessed-variable=PRP_SR_CFG_TYPE_ILV.CFG_TYPE_ILV
            Dwa_SR_CFG_OPTION_HADC_CFG_OPTION_HADC: accessed-variable=PRP_SR_CFG_OPTION_HADC.CFG_OPTION_HADC
            Dwa_SR_CFG_TYPE_LANE_ASSIST_CFG_TYPE_LANE_ASSIST: accessed-variable=PRP_SR_CFG_TYPE_LANE_ASSIST.CFG_TYPE_LANE_ASSIST
            Dwa_SR_CFG_TYPE_DRIVER_ASSIST_CFG_TYPE_DRIVER_ASSIST: accessed-variable=PRP_SR_CFG_TYPE_DRIVER_ASSIST.CFG_TYPE_DRIVER_ASSIST
            Dwa_SR_CFG_PRESENCE_CABIN_AQI_SENSOR_CFG_PRESENCE_CABIN_AQI_SENSOR: accessed-variable=PRP_SR_CFG_PRESENCE_CABIN_AQI_SENSOR.CFG_PRESENCE_CABIN_AQI_SENSOR
            Dwa_SR_CFG_MODUL_STTCONFORT_CFG_MODUL_STTCONFORT: accessed-variable=PRP_SR_CFG_MODUL_STTCONFORT.CFG_MODUL_STTCONFORT
            Dwa_SR_CFG_RAPENTR_CFG_RAPENTR: accessed-variable=PRP_SR_CFG_RAPENTR.CFG_RAPENTR
            Dwa_SR_CFG_MODUL_POLLUT_CFG_MODUL_POLLUT: accessed-variable=PRP_SR_CFG_MODUL_POLLUT.CFG_MODUL_POLLUT
            Dwa_SR_CFG_MODUL_CPR_CFG_MODUL_CPR: accessed-variable=PRP_SR_CFG_MODUL_CPR.CFG_MODUL_CPR
            Dwa_SR_CFG_MODUL_CTP_CFG_MODUL_CTP: accessed-variable=PRP_SR_CFG_MODUL_CTP.CFG_MODUL_CTP
            Dwa_SR_CFG_MODUL_DEBIT_AERO_CFG_MODUL_DEBIT_AERO: accessed-variable=PRP_SR_CFG_MODUL_DEBIT_AERO.CFG_MODUL_DEBIT_AERO
            Dwa_SR_CFG_MODUL_FMUX_CFG_MODUL_FMUX: accessed-variable=PRP_SR_CFG_MODUL_FMUX.CFG_MODUL_FMUX
            Dwa_SR_CFG_MODUL_RECHAUFFEUR_CFG_MODUL_RECHAUFFEUR: accessed-variable=PRP_SR_CFG_MODUL_RECHAUFFEUR.CFG_MODUL_RECHAUFFEUR
            Dwa_SR_CFG_MODUL_PROG_PRECOND_CFG_MODUL_PROG_PRECOND: accessed-variable=PRP_SR_CFG_MODUL_PROG_PRECOND.CFG_MODUL_PROG_PRECOND
            Dwa_SR_CFG_PRESENCE_CIELO_CFG_PRESENCE_CIELO: accessed-variable=PRP_SR_CFG_PRESENCE_CIELO.CFG_PRESENCE_CIELO
            Dwa_SR_CFG_MODUL_TAS_CFG_MODUL_TAS: accessed-variable=PRP_SR_CFG_MODUL_TAS.CFG_MODUL_TAS
            Dwa_SR_CFG_MODUL_SOL_CFG_MODUL_SOL: accessed-variable=PRP_SR_CFG_MODUL_SOL.CFG_MODUL_SOL
            Dwa_SR_CFG_MODUL_DCT_CFG_MODUL_DCT: accessed-variable=PRP_SR_CFG_MODUL_DCT.CFG_MODUL_DCT
            Dwa_SR_CFG_TYPE_CLIM_CFG_TYPE_CLIM: accessed-variable=PRP_SR_CFG_TYPE_CLIM.CFG_TYPE_CLIM
            Dwa_SR_CFG_TYPE_ARCHI_IHM_CLIM_CFG_TYPE_ARCHI_IHM_CLIM: accessed-variable=PRP_SR_CFG_TYPE_ARCHI_IHM_CLIM.CFG_TYPE_ARCHI_IHM_CLIM
            Dwa_SR_CFG_TYPE_IHM_DISTRIB_AV_TACT_CFG_TYPE_IHM_DISTRIB_AV_TACT: accessed-variable=PRP_SR_CFG_TYPE_IHM_DISTRIB_AV_TACT.CFG_TYPE_IHM_DISTRIB_AV_TACT
            Dwa_SR_CFG_TYPE_IHM_ENTREE_AIR_PHYS_CFG_TYPE_IHM_ENTREE_AIR_PHYS: accessed-variable=PRP_SR_CFG_TYPE_IHM_ENTREE_AIR_PHYS.CFG_TYPE_IHM_ENTREE_AIR_PHYS
            Dwa_SR_CFG_TYPE_IHM_PULSEUR_AR_CFG_TYPE_IHM_PULSEUR_AR: accessed-variable=PRP_SR_CFG_TYPE_IHM_PULSEUR_AR.CFG_TYPE_IHM_PULSEUR_AR
            Dwa_SR_CFG_TYPE_IHM_PULSEUR_AV_PHYS_CFG_TYPE_IHM_PULSEUR_AV_PHYS: accessed-variable=PRP_SR_CFG_TYPE_IHM_PULSEUR_AV_PHYS.CFG_TYPE_IHM_PULSEUR_AV_PHYS
            Dwa_SR_CFG_TYPE_IHM_PULSEUR_AV_TACT_CFG_TYPE_IHM_PULSEUR_AV_TACT: accessed-variable=PRP_SR_CFG_TYPE_IHM_PULSEUR_AV_TACT.CFG_TYPE_IHM_PULSEUR_AV_TACT
            Dwa_SR_CFG_TYPE_IHM_PULSEUR_RG3_CFG_TYPE_IHM_PULSEUR_RG3: accessed-variable=PRP_SR_CFG_TYPE_IHM_PULSEUR_RG3.CFG_TYPE_IHM_PULSEUR_RG3
            Dwa_SR_CFG_TYPE_IHM_TEMP_AV_PHYS_CFG_TYPE_IHM_TEMP_AV_PHYS: accessed-variable=PRP_SR_CFG_TYPE_IHM_TEMP_AV_PHYS.CFG_TYPE_IHM_TEMP_AV_PHYS
            Dwa_SR_CFG_TYPE_IHM_TEMP_AV_TACT_CFG_TYPE_IHM_TEMP_AV_TACT: accessed-variable=PRP_SR_CFG_TYPE_IHM_TEMP_AV_TACT.CFG_TYPE_IHM_TEMP_AV_TACT
            Dwa_SR_CFG_TYPE_IHM_TYPAGE_AUTO_CFG_TYPE_IHM_TYPAGE_AUTO: accessed-variable=PRP_SR_CFG_TYPE_IHM_TYPAGE_AUTO.CFG_TYPE_IHM_TYPAGE_AUTO
            Dwa_SR_CFG_TYPE_FAP_CFG_TYPE_FAP: accessed-variable=PRP_SR_CFG_TYPE_FAP.CFG_TYPE_FAP
            Dwa_SR_CFG_NumTable_NH_CFG_NumTable_NH: accessed-variable=PRP_SR_CFG_NumTable_NH.CFG_NumTable_NH
            Dwa_SR_CFG_ORIGINE_NHUILE_CFG_ORIGINE_NHUILE: accessed-variable=PRP_SR_CFG_ORIGINE_NHUILE.CFG_ORIGINE_NHUILE
            Dwa_SR_CFG_PRESENCE_AUTO_INHIB_RBG_PASS_CFG_PRESENCE_AUTO_INHIB_RBG_PASS: accessed-variable=PRP_SR_CFG_PRESENCE_AUTO_INHIB_RBG_PASS.CFG_PRESENCE_AUTO_INHIB_RBG_PASS
            Dwa_SR_CFG_PRESENCE_DSG_CFG_PRESENCE_DSG: accessed-variable=PRP_SR_CFG_PRESENCE_DSG.CFG_PRESENCE_DSG
            Dwa_SR_CFG_TYPE_PUSH_DSGI_CFG_TYPE_PUSH_DSGI: accessed-variable=PRP_SR_CFG_TYPE_PUSH_DSGI.CFG_TYPE_PUSH_DSGI
            Dwa_SR_CFG_PRESENCE_AVE_CFG_PRESENCE_AVE: accessed-variable=PRP_SR_CFG_PRESENCE_AVE.CFG_PRESENCE_AVE
            Dwa_SR_CFG_TYPE_CHAINE_TRACTION_CFG_TYPE_CHAINE_TRACTION: accessed-variable=PRP_SR_CFG_TYPE_CHAINE_TRACTION.CFG_TYPE_CHAINE_TRACTION
            Dwa_SR_CFG_TYPE_DEMARRAGE_CFG_TYPE_DEMARRAGE: accessed-variable=PRP_SR_CFG_TYPE_DEMARRAGE.CFG_TYPE_DEMARRAGE
            Dwa_SR_CFG_TYPE_GMP_CFG_TYPE_GMP: accessed-variable=PRP_SR_CFG_TYPE_GMP.CFG_TYPE_GMP
            Dwa_SR_CFG_PRESENCE_FARC_CFG_PRESENCE_FARC: accessed-variable=PRP_SR_CFG_PRESENCE_FARC.CFG_PRESENCE_FARC
            Dwa_SR_CFG_PRESENCE_ARC_CFG_PRESENCE_ARC: accessed-variable=PRP_SR_CFG_PRESENCE_ARC.CFG_PRESENCE_ARC
            Dwa_SR_CFG_AMVAR_CFG_AMVAR: accessed-variable=PRP_SR_CFG_AMVAR.CFG_AMVAR
            Dwa_SR_TYPE_HMI_MODE_SELECTOR_TYPE_HMI_MODE_SELECTOR: accessed-variable=PRP_SR_TYPE_HMI_MODE_SELECTOR.TYPE_HMI_MODE_SELECTOR
            Dwa_SR_CFG_PRESENCE_MODE_ECO_DYN_CFG_PRESENCE_MODE_ECO_DYN: accessed-variable=PRP_SR_CFG_PRESENCE_MODE_ECO_DYN.CFG_PRESENCE_MODE_ECO_DYN
            Dwa_SR_CFG_PRESENCE_MEAP_CFG_PRESENCE_MEAP: accessed-variable=PRP_SR_CFG_PRESENCE_MEAP.CFG_PRESENCE_MEAP
            Dwa_SR_CFG_POLYSENSORIAL_PACK_CFG_POLYSENSORIAL_PACK: accessed-variable=PRP_SR_CFG_POLYSENSORIAL_PACK.CFG_POLYSENSORIAL_PACK
            Dwa_SR_CFG_PRESENCE_MODE_SPORT_DYN_CFG_PRESENCE_MODE_SPORT_DYN: accessed-variable=PRP_SR_CFG_PRESENCE_MODE_SPORT_DYN.CFG_PRESENCE_MODE_SPORT_DYN
            Dwa_SR_CFG_OPTION_SONDE_EAU_GAZOLE_CFG_OPTION_SONDE_EAU_GAZOLE: accessed-variable=PRP_SR_CFG_OPTION_SONDE_EAU_GAZOLE.CFG_OPTION_SONDE_EAU_GAZOLE
            Dwa_SR_CFG_TYPE_PACK_DYN_CFG_TYPE_PACK_DYN: accessed-variable=PRP_SR_CFG_TYPE_PACK_DYN.CFG_TYPE_PACK_DYN
            Dwa_SR_CFG_AUTOR_MAP_HMI_CFG_AUTOR_MAP_HMI: accessed-variable=PRP_SR_CFG_AUTOR_MAP_HMI.CFG_AUTOR_MAP_HMI
            Dwa_SR_CFG_FCT_GSI_CFG_FCT_GSI: accessed-variable=PRP_SR_CFG_FCT_GSI.CFG_FCT_GSI
            Dwa_SR_CFG_TYPE_BOITE_CFG_TYPE_BOITE: accessed-variable=PRP_SR_CFG_TYPE_BOITE.CFG_TYPE_BOITE
            Dwa_SR_CFG_TYPE_SC_CFG_TYPE_SC: accessed-variable=PRP_SR_CFG_TYPE_SC.CFG_TYPE_SC
            Dwa_SR_CFG_ACQ_PUSH_ESP_CFG_ACQ_PUSH_ESP: accessed-variable=PRP_SR_CFG_ACQ_PUSH_ESP.CFG_ACQ_PUSH_ESP
            Dwa_SR_CFG_PRESENCE_ASR_PLUS_CFG_PRESENCE_ASR_PLUS: accessed-variable=PRP_SR_CFG_PRESENCE_ASR_PLUS.CFG_PRESENCE_ASR_PLUS
            Dwa_SR_CFG_OPTION_HBB_HBC_CFG_OPTION_HBB_HBC: accessed-variable=PRP_SR_CFG_OPTION_HBB_HBC.CFG_OPTION_HBB_HBC
            Dwa_SR_CFG_OPTION_PLV_CFG_OPTION_PLV: accessed-variable=PRP_SR_CFG_OPTION_PLV.CFG_OPTION_PLV
            Dwa_SR_CFG_PRESENCE_LVVRVV_CFG_PRESENCE_LVVRVV: accessed-variable=PRP_SR_CFG_PRESENCE_LVVRVV.CFG_PRESENCE_LVVRVV
            Dwa_SR_CFG_TYPE_ACC_CFG_TYPE_ACC: accessed-variable=PRP_SR_CFG_TYPE_ACC.CFG_TYPE_ACC
            Dwa_SR_CFG_TYPE_TARGET_DETECTION_CFG_TYPE_TARGET_DETECTION: accessed-variable=PRP_SR_CFG_TYPE_TARGET_DETECTION.CFG_TYPE_TARGET_DETECTION
            Dwa_SR_CFG_TYPE_AQUI_PUSH_STT_CFG_TYPE_AQUI_PUSH_STT: accessed-variable=PRP_SR_CFG_TYPE_AQUI_PUSH_STT.CFG_TYPE_AQUI_PUSH_STT
            Dwa_SR_CFG_TYPE_STT_CFG_TYPE_STT: accessed-variable=PRP_SR_CFG_TYPE_STT.CFG_TYPE_STT
            Dwa_SR_CFG_TypeCPK_CFG_TypeCPK: accessed-variable=PRP_SR_CFG_TypeCPK.CFG_TypeCPK
            Dwa_SR_CFG_OPTION_SAM_CFG_OPTION_SAM: accessed-variable=PRP_SR_CFG_OPTION_SAM.CFG_OPTION_SAM
            Dwa_SR_CFG_PRESENCE_PUSH_SAM_CFG_PRESENCE_PUSH_SAM: accessed-variable=PRP_SR_CFG_PRESENCE_PUSH_SAM.CFG_PRESENCE_PUSH_SAM
            Dwa_SR_CFG_OPTION_DOP_CFG_OPTION_DOP: accessed-variable=PRP_SR_CFG_OPTION_DOP.CFG_OPTION_DOP
            Dwa_SR_CFG_PRESENCE_ECOACH_CFG_PRESENCE_ECOACH: accessed-variable=PRP_SR_CFG_PRESENCE_ECOACH.CFG_PRESENCE_ECOACH
            Dwa_SR_CFG_NIV_ALERTE_MINI_CARB_CFG_NIV_ALERTE_MINI_CARB: accessed-variable=PRP_SR_CFG_NIV_ALERTE_MINI_CARB.CFG_NIV_ALERTE_MINI_CARB
            Dwa_SR_C7D_NIV_CARB_CRITIQUE_C7D_NIV_CARB_CRITIQUE: accessed-variable=PRP_SR_C7D_NIV_CARB_CRITIQUE.C7D_NIV_CARB_CRITIQUE
            Dwa_SR_CFG_NUM_TABLE_CARB_CFG_NUM_TABLE_CARB: accessed-variable=PRP_SR_CFG_NUM_TABLE_CARB.CFG_NUM_TABLE_CARB
            Dwa_SR_CfgTypeLocksSteering_CfgTypeLocksSteering: accessed-variable=PRP_SR_CfgTypeLocksSteering.CfgTypeLocksSteering
            Dwa_SR_CFG_OPTION_BLUETOOTH_CFG_OPTION_BLUETOOTH: accessed-variable=PRP_SR_CFG_OPTION_BLUETOOTH.CFG_OPTION_BLUETOOTH
            Dwa_SR_CFG_OPTION_BAA_CFG_OPTION_BAA: accessed-variable=PRP_SR_CFG_OPTION_BAA.CFG_OPTION_BAA
            Dwa_SR_CfgTypeTrunkPushInterior_CfgTypeTrunkPushInterior: accessed-variable=PRP_SR_CfgTypeTrunkPushInterior.CfgTypeTrunkPushInterior
            Dwa_SR_CfgTypeRearOpening_CfgTypeRearOpening: accessed-variable=PRP_SR_CfgTypeRearOpening.CfgTypeRearOpening
            Dwa_SR_CFG_VOLET_MOTORISE_CFG_VOLET_MOTORISE: accessed-variable=PRP_SR_CFG_VOLET_MOTORISE.CFG_VOLET_MOTORISE
            Dwa_SR_CfgSelectivityDoors_CfgSelectivityDoors: accessed-variable=PRP_SR_CfgSelectivityDoors.CfgSelectivityDoors
            Dwa_SR_CFG_STEERING_WHEEL_POSITION_CFG_STEERING_WHEEL_POSITION: accessed-variable=PRP_SR_CFG_STEERING_WHEEL_POSITION.CFG_STEERING_WHEEL_POSITION
            Dwa_SR_CFG_CONDA_CFG_CONDA: accessed-variable=PRP_SR_CFG_CONDA.CFG_CONDA
            Dwa_SR_CFG_PLIP_TOUCH_3_FUNCTION_CFG_PLIP_TOUCH_3_FUNCTION: accessed-variable=PRP_SR_CFG_PLIP_TOUCH_3_FUNCTION.CFG_PLIP_TOUCH_3_FUNCTION
            Dwa_SR_CFG_PLIP_WL_FUNCTIONNALITY_CFG_PLIP_WL_FUNCTIONNALITY: accessed-variable=PRP_SR_CFG_PLIP_WL_FUNCTIONNALITY.CFG_PLIP_WL_FUNCTIONNALITY
            Dwa_SR_CFG_PLIP_WL_BEHAVIOR_CFG_PLIP_WL_BEHAVIOR: accessed-variable=PRP_SR_CFG_PLIP_WL_BEHAVIOR.CFG_PLIP_WL_BEHAVIOR
            Dwa_SR_CFG_PLIP_PRESS_TYPE_TOUCH_3_CFG_PLIP_PRESS_TYPE_TOUCH_3: accessed-variable=PRP_SR_CFG_PLIP_PRESS_TYPE_TOUCH_3.CFG_PLIP_PRESS_TYPE_TOUCH_3
            Dwa_SR_CFG_DRIVER_LOCK_TYPE_CFG_DRIVER_LOCK_TYPE: accessed-variable=PRP_SR_CFG_DRIVER_LOCK_TYPE.CFG_DRIVER_LOCK_TYPE
            Dwa_SR_CFG_FUEL_FLAP_LOCK_TYPE_CFG_FUEL_FLAP_LOCK_TYPE: accessed-variable=PRP_SR_CFG_FUEL_FLAP_LOCK_TYPE.CFG_FUEL_FLAP_LOCK_TYPE
            Dwa_SR_CFG_HOOD_LOCK_TYPE_CFG_HOOD_LOCK_TYPE: accessed-variable=PRP_SR_CFG_HOOD_LOCK_TYPE.CFG_HOOD_LOCK_TYPE
            Dwa_SR_CFG_REAR_LEFT_LOCK_TYPE_CFG_REAR_LEFT_LOCK_TYPE: accessed-variable=PRP_SR_CFG_REAR_LEFT_LOCK_TYPE.CFG_REAR_LEFT_LOCK_TYPE
            Dwa_SR_CFG_REAR_RIGHT_LOCK_TYPE_CFG_REAR_RIGHT_LOCK_TYPE: accessed-variable=PRP_SR_CFG_REAR_RIGHT_LOCK_TYPE.CFG_REAR_RIGHT_LOCK_TYPE
            Dwa_SR_CFG_OPTION_SUNROOF_CFG_OPTION_SUNROOF: accessed-variable=PRP_SR_CFG_OPTION_SUNROOF.CFG_OPTION_SUNROOF
            Dwa_SR_CfgRearViewMirrorIndexingReverseGear_CfgRearViewMirrorIndexingReverseGear: accessed-variable=PRP_SR_CfgRearViewMirrorIndexingReverseGear.CfgRearViewMirrorIndexingReverseGear
            Dwa_SR_CFG_OPTION_SIEGE_CLIM_CFG_OPTION_SIEGE_CLIM: accessed-variable=PRP_SR_CFG_OPTION_SIEGE_CLIM.CFG_OPTION_SIEGE_CLIM
            Dwa_SR_CFG_PRES_VOLANT_CHAUF_CFG_PRES_VOLANT_CHAUF: accessed-variable=PRP_SR_CFG_PRES_VOLANT_CHAUF.CFG_PRES_VOLANT_CHAUF
            Dwa_SR_CFG_TYPE_SOC_CFG_TYPE_SOC: accessed-variable=PRP_SR_CFG_TYPE_SOC.CFG_TYPE_SOC
            Dwa_SR_CFG_OPTION_VISION_NOCTURNE_CFG_OPTION_VISION_NOCTURNE: accessed-variable=PRP_SR_CFG_OPTION_VISION_NOCTURNE.CFG_OPTION_VISION_NOCTURNE
            Dwa_SR_CFG_AUTOR_MAP_ECLI_CFG_AUTOR_MAP_ECLI: accessed-variable=PRP_SR_CFG_AUTOR_MAP_ECLI.CFG_AUTOR_MAP_ECLI
            Dwa_SR_CFG_POLYCHROME_AMB_CFG_POLYCHROME_AMB: accessed-variable=PRP_SR_CFG_POLYCHROME_AMB.CFG_POLYCHROME_AMB
            Dwa_SR_CFG_OPTION_AFS_CFG_OPTION_AFS: accessed-variable=PRP_SR_CFG_OPTION_AFS.CFG_OPTION_AFS
            Dwa_SR_CFG_OPTION_ECL_INTERSEC_CFG_OPTION_ECL_INTERSEC: accessed-variable=PRP_SR_CFG_OPTION_ECL_INTERSEC.CFG_OPTION_ECL_INTERSEC
            Dwa_SR_CFG_OPTION_ECL_VIR_STAT_CFG_OPTION_ECL_VIR_STAT: accessed-variable=PRP_SR_CFG_OPTION_ECL_VIR_STAT.CFG_OPTION_ECL_VIR_STAT
            Dwa_SR_CFG_OPTION_ANTIBR_AV_CFG_OPTION_ANTIBR_AV: accessed-variable=PRP_SR_CFG_OPTION_ANTIBR_AV.CFG_OPTION_ANTIBR_AV
            Dwa_SR_CFG_TypeEclairageAV_CFG_TypeEclairageAV: accessed-variable=PRP_SR_CFG_TypeEclairageAV.CFG_TypeEclairageAV
            Dwa_SR_CFG_PRESENCE_BSG_RQ_CFG_PRESENCE_BSG_RQ: accessed-variable=PRP_SR_CFG_PRESENCE_BSG_RQ.CFG_PRESENCE_BSG_RQ
            Dwa_SR_CFG_INHIB_MOVING_EFFECT_CFG_INHIB_MOVING_EFFECT: accessed-variable=PRP_SR_CFG_INHIB_MOVING_EFFECT.CFG_INHIB_MOVING_EFFECT
            Dwa_SR_CFG_FONCTION_AHB_CFG_FONCTION_AHB: accessed-variable=PRP_SR_CFG_FONCTION_AHB.CFG_FONCTION_AHB
            Dwa_SR_CFG_OPTION_AAF_CFG_OPTION_AAF: accessed-variable=PRP_SR_CFG_OPTION_AAF.CFG_OPTION_AAF
            Dwa_SR_CFG_TYPE_COMODO_CFG_TYPE_COMODO: accessed-variable=PRP_SR_CFG_TYPE_COMODO.CFG_TYPE_COMODO
            Dwa_SR_CFG_Barrette_TNB_sur_LIN_CFG_Barrette_TNB_sur_LIN: accessed-variable=PRP_SR_CFG_Barrette_TNB_sur_LIN.CFG_Barrette_TNB_sur_LIN
            Dwa_SR_CFG_INHIB_DIAG_TNB_COND_CFG_INHIB_DIAG_TNB_COND: accessed-variable=PRP_SR_CFG_INHIB_DIAG_TNB_COND.CFG_INHIB_DIAG_TNB_COND
            Dwa_SR_CFG_INHIB_DIAG_TNB_PAR2C_CFG_INHIB_DIAG_TNB_PAR2C: accessed-variable=PRP_SR_CFG_INHIB_DIAG_TNB_PAR2C.CFG_INHIB_DIAG_TNB_PAR2C
            Dwa_SR_CFG_INHIB_DIAG_TNB_PAR2D_CFG_INHIB_DIAG_TNB_PAR2D: accessed-variable=PRP_SR_CFG_INHIB_DIAG_TNB_PAR2D.CFG_INHIB_DIAG_TNB_PAR2D
            Dwa_SR_CFG_INHIB_DIAG_TNB_PAR2G_CFG_INHIB_DIAG_TNB_PAR2G: accessed-variable=PRP_SR_CFG_INHIB_DIAG_TNB_PAR2G.CFG_INHIB_DIAG_TNB_PAR2G
            Dwa_SR_CFG_OPTION_TAXI_CFG_OPTION_TAXI: accessed-variable=PRP_SR_CFG_OPTION_TAXI.CFG_OPTION_TAXI
            Dwa_SR_CFG_INHIB_DIAG_TNB_PAV_CFG_INHIB_DIAG_TNB_PAV: accessed-variable=PRP_SR_CFG_INHIB_DIAG_TNB_PAV.CFG_INHIB_DIAG_TNB_PAV
            Dwa_SR_CFG_NAPPE_DETECTION_PASS_CFG_NAPPE_DETECTION_PASS: accessed-variable=PRP_SR_CFG_NAPPE_DETECTION_PASS.CFG_NAPPE_DETECTION_PASS
            Dwa_SR_CFG_NBR_CNB_CFG_NBR_CNB: accessed-variable=PRP_SR_CFG_NBR_CNB.CFG_NBR_CNB
            Dwa_SR_CFG_TYPE_PRES_PASS_SENSOR_CFG_TYPE_PRES_PASS_SENSOR: accessed-variable=PRP_SR_CFG_TYPE_PRES_PASS_SENSOR.CFG_TYPE_PRES_PASS_SENSOR
            Dwa_SR_CFG_PRESENCE_OPTION_MEMORISATION_CFG_PRESENCE_OPTION_MEMORISATION: accessed-variable=PRP_SR_CFG_PRESENCE_OPTION_MEMORISATION.CFG_PRESENCE_OPTION_MEMORISATION
            Dwa_SR_CFG_WELCOME_DRIVER_SEAT_FUNCTION_CFG_WELCOME_DRIVER_SEAT_FUNCTION: accessed-variable=PRP_SR_CFG_WELCOME_DRIVER_SEAT_FUNCTION.CFG_WELCOME_DRIVER_SEAT_FUNCTION
            Dwa_SR_CFG_OPTION_MASSAGE_CFG_OPTION_MASSAGE: accessed-variable=PRP_SR_CFG_OPTION_MASSAGE.CFG_OPTION_MASSAGE
            Dwa_SR_CFG_PRESENCE_VTH_CFG_PRESENCE_VTH: accessed-variable=PRP_SR_CFG_PRESENCE_VTH.CFG_PRESENCE_VTH
            Dwa_SR_CFG_MEMO_REGL_RETROS_CFG_MEMO_REGL_RETROS: accessed-variable=PRP_SR_CFG_MEMO_REGL_RETROS.CFG_MEMO_REGL_RETROS
            Dwa_SR_CFG_PRESENCE_PBC_CFG_PRESENCE_PBC: accessed-variable=PRP_SR_CFG_PRESENCE_PBC.CFG_PRESENCE_PBC
            Dwa_SR_CFG_CLIMAT_CFG_CLIMAT: accessed-variable=PRP_SR_CFG_CLIMAT.CFG_CLIMAT
            Dwa_SR_CfgTypeFrontDefrost_CfgTypeFrontDefrost: accessed-variable=PRP_SR_CfgTypeFrontDefrost.CfgTypeFrontDefrost
            Dwa_SR_CFG_TYPE_MODUL_OPTI_VIDE_CFG_TYPE_MODUL_OPTI_VIDE: accessed-variable=PRP_SR_CFG_TYPE_MODUL_OPTI_VIDE.CFG_TYPE_MODUL_OPTI_VIDE
            Dwa_SR_CfgSweepingCourtesy_CfgSweepingCourtesy: accessed-variable=PRP_SR_CfgSweepingCourtesy.CfgSweepingCourtesy
            Dwa_SR_CfgRainSensor_CfgRainSensor: accessed-variable=PRP_SR_CfgRainSensor.CfgRainSensor
            Dwa_SR_SCR_AFFICH_POI_ADBLUE_SCR_AFFICH_POI_ADBLUE: accessed-variable=PRP_SR_SCR_AFFICH_POI_ADBLUE.SCR_AFFICH_POI_ADBLUE
            Dwa_SR_CFG_PRESENCE_SCR_CFG_PRESENCE_SCR: accessed-variable=PRP_SR_CFG_PRESENCE_SCR.CFG_PRESENCE_SCR
            Dwa_SR_CFG_DISPO_PSEUDO_CONSO_CARB_CFG_DISPO_PSEUDO_CONSO_CARB: accessed-variable=PRP_SR_CFG_DISPO_PSEUDO_CONSO_CARB.CFG_DISPO_PSEUDO_CONSO_CARB
            Dwa_SR_CFG_EngineMaintType_CFG_EngineMaintType: accessed-variable=PRP_SR_CFG_EngineMaintType.CFG_EngineMaintType
            Dwa_SR_M230_TimeFirstMaint_M230_TimeFirstMaint: accessed-variable=PRP_SR_M230_TimeFirstMaint.M230_TimeFirstMaint
            Dwa_SR_M230_TimeOtherMaint_M230_TimeOtherMaint: accessed-variable=PRP_SR_M230_TimeOtherMaint.M230_TimeOtherMaint
            Dwa_SR_M230_KmFirstMaint_M230_KmFirstMaint: accessed-variable=PRP_SR_M230_KmFirstMaint.M230_KmFirstMaint
            Dwa_SR_M230_KmOtherMaint_M230_KmOtherMaint: accessed-variable=PRP_SR_M230_KmOtherMaint.M230_KmOtherMaint
            Dwa_SR_M230_KmOrTimeMaint_M230_KmOrTimeMaint: accessed-variable=PRP_SR_M230_KmOrTimeMaint.M230_KmOrTimeMaint
            Dwa_SR_CFG_DISTRACTION_MODE_CFG_DISTRACTION_MODE: accessed-variable=PRP_SR_CFG_DISTRACTION_MODE.CFG_DISTRACTION_MODE
            Dwa_SR_CFG_PresenceCRT_CFG_PresenceCRT: accessed-variable=PRP_SR_CFG_PresenceCRT.CFG_PresenceCRT
            Dwa_SR_CFG_TYPE_BTEL_CFG_TYPE_BTEL: accessed-variable=PRP_SR_CFG_TYPE_BTEL.CFG_TYPE_BTEL
            Dwa_SR_CFG_SOFTWARE_UPDATE_CAPABILITY_CFG_SOFTWARE_UPDATE_CAPABILITY: accessed-variable=PRP_SR_CFG_SOFTWARE_UPDATE_CAPABILITY.CFG_SOFTWARE_UPDATE_CAPABILITY
            Dwa_SR_DiagCodeVIN_DiagCodeVIN_{01..17}: accessed-variable=PRP_SR_DiagCodeVIN.DiagCodeVIN_{01..17}
            Dwa_SR_CFG_SMARTDEVICE_BY_SDCM_CFG_SMARTDEVICE_BY_SDCM: accessed-variable=PRP_SR_CFG_SMARTDEVICE_BY_SDCM.CFG_SMARTDEVICE_BY_SDCM
            Dwa_SR_CFG_AUTOR_MAP_INVIO_CFG_AUTOR_MAP_INVIO: accessed-variable=PRP_SR_CFG_AUTOR_MAP_INVIO.CFG_AUTOR_MAP_INVIO
            Dwa_SR_CFG_GEN_RSK16_CFG_GEN_RSK16: accessed-variable=PRP_SR_CFG_GEN_RSK16.CFG_GEN_RSK16
            Dwa_SR_CFG_OPTION_WLC_CFG_OPTION_WLC: accessed-variable=PRP_SR_CFG_OPTION_WLC.CFG_OPTION_WLC
            Dwa_SR_CFG_TYPE_CLE_CFG_TYPE_CLE: accessed-variable=PRP_SR_CFG_TYPE_CLE.CFG_TYPE_CLE
            Dwa_SR_CFG_ALARME_2NDE_MONTE_CFG_ALARME_2NDE_MONTE: accessed-variable=PRP_SR_CFG_ALARME_2NDE_MONTE.CFG_ALARME_2NDE_MONTE
            Dwa_SR_CFG_INHIB_VOLUMETRIE_CFG_INHIB_VOLUMETRIE: accessed-variable=PRP_SR_CFG_INHIB_VOLUMETRIE.CFG_INHIB_VOLUMETRIE
            Dwa_SR_CFG_PRESENCE_MUS_LIN_CFG_PRESENCE_MUS_LIN: accessed-variable=PRP_SR_CFG_PRESENCE_MUS_LIN.CFG_PRESENCE_MUS_LIN
            Dwa_SR_CFG_PRESENCE_SIRENE_LIN_CFG_PRESENCE_SIRENE_LIN: accessed-variable=PRP_SR_CFG_PRESENCE_SIRENE_LIN.CFG_PRESENCE_SIRENE_LIN
            Dwa_SR_CFG_TYPE_ALARME_CFG_TYPE_ALARME: accessed-variable=PRP_SR_CFG_TYPE_ALARME.CFG_TYPE_ALARME
            Dwa_SR_CFG_OPTIONS_TLM_CFG_OPTIONS_TLM: accessed-variable=PRP_SR_CFG_OPTIONS_TLM.CFG_OPTIONS_TLM
            Dwa_SR_CFG_PROCESS_USINE_{01..06}_CFG_PROCESS_USINE_{01..06}: accessed-variable=PRP_SR_CFG_PROCESS_USINE_{01..06}.CFG_PROCESS_USINE_{01..06}
            Dwa_SR_CFG_DATE_TELECODAGE_{1..3}_CFG_DATE_TELECODAGE_{1..3}: accessed-variable=PRP_SR_CFG_DATE_TELECODAGE_{1..3}.CFG_DATE_TELECODAGE_{1..3}
            Dwa_SR_CFG_SIGNATURE_OUTIL_{1..3}_CFG_SIGNATURE_OUTIL_{1..3}: accessed-variable=PRP_SR_CFG_SIGNATURE_OUTIL_{1..3}.CFG_SIGNATURE_OUTIL_{1..3}
            Dwa_SR_CFG_SITE_TELECODAGE_CFG_SITE_TELECODAGE: accessed-variable=PRP_SR_CFG_SITE_TELECODAGE.CFG_SITE_TELECODAGE
            Dwa_SR_CFG_UCE_{001..026}_CFG_UCE_{001..026}: accessed-variable=PRP_SR_CFG_UCE_{001..026}.CFG_UCE_{001..026}
            Dwa_SR_CFG_UCE_{028..069}_CFG_UCE_{028..069}: accessed-variable=PRP_SR_CFG_UCE_{028..069}.CFG_UCE_{028..069}
      runnable RUNMO_Aswc_IntDcm
        data-read-access:
          253 x access:
            Dra_SR_CFG_DEF_VEHICULE_CFG_DEF_VEHICULE: accessed-variable=PRP_SR_CFG_DEF_VEHICULE.CFG_DEF_VEHICULE
            Dra_SR_CFG_PRESENCE_ETSR_CFG_PRESENCE_ETSR: accessed-variable=PRP_SR_CFG_PRESENCE_ETSR.CFG_PRESENCE_ETSR
            Dra_SR_CFG_NAV_POI_RADAR_CFG_NAV_POI_RADAR: accessed-variable=PRP_SR_CFG_NAV_POI_RADAR.CFG_NAV_POI_RADAR
            Dra_SR_CFG_OPT_ANTICIPATED_PLV_CFG_OPT_ANTICIPATED_PLV: accessed-variable=PRP_SR_CFG_OPT_ANTICIPATED_PLV.CFG_OPT_ANTICIPATED_PLV
            Dra_SR_CFG_TYPE_ILV_CFG_TYPE_ILV: accessed-variable=PRP_SR_CFG_TYPE_ILV.CFG_TYPE_ILV
            Dra_SR_CFG_OPTION_HADC_CFG_OPTION_HADC: accessed-variable=PRP_SR_CFG_OPTION_HADC.CFG_OPTION_HADC
            Dra_SR_CFG_TYPE_LANE_ASSIST_CFG_TYPE_LANE_ASSIST: accessed-variable=PRP_SR_CFG_TYPE_LANE_ASSIST.CFG_TYPE_LANE_ASSIST
            Dra_SR_CFG_TYPE_DRIVER_ASSIST_CFG_TYPE_DRIVER_ASSIST: accessed-variable=PRP_SR_CFG_TYPE_DRIVER_ASSIST.CFG_TYPE_DRIVER_ASSIST
            Dra_SR_CFG_PRESENCE_CABIN_AQI_SENSOR_CFG_PRESENCE_CABIN_AQI_SENSOR: accessed-variable=PRP_SR_CFG_PRESENCE_CABIN_AQI_SENSOR.CFG_PRESENCE_CABIN_AQI_SENSOR
            Dra_SR_CFG_MODUL_STTCONFORT_CFG_MODUL_STTCONFORT: accessed-variable=PRP_SR_CFG_MODUL_STTCONFORT.CFG_MODUL_STTCONFORT
            Dra_SR_CFG_RAPENTR_CFG_RAPENTR: accessed-variable=PRP_SR_CFG_RAPENTR.CFG_RAPENTR
            Dra_SR_CFG_MODUL_POLLUT_CFG_MODUL_POLLUT: accessed-variable=PRP_SR_CFG_MODUL_POLLUT.CFG_MODUL_POLLUT
            Dra_SR_CFG_MODUL_CPR_CFG_MODUL_CPR: accessed-variable=PRP_SR_CFG_MODUL_CPR.CFG_MODUL_CPR
            Dra_SR_CFG_MODUL_CTP_CFG_MODUL_CTP: accessed-variable=PRP_SR_CFG_MODUL_CTP.CFG_MODUL_CTP
            Dra_SR_CFG_MODUL_DEBIT_AERO_CFG_MODUL_DEBIT_AERO: accessed-variable=PRP_SR_CFG_MODUL_DEBIT_AERO.CFG_MODUL_DEBIT_AERO
            Dra_SR_CFG_MODUL_FMUX_CFG_MODUL_FMUX: accessed-variable=PRP_SR_CFG_MODUL_FMUX.CFG_MODUL_FMUX
            Dra_SR_CFG_MODUL_RECHAUFFEUR_CFG_MODUL_RECHAUFFEUR: accessed-variable=PRP_SR_CFG_MODUL_RECHAUFFEUR.CFG_MODUL_RECHAUFFEUR
            Dra_SR_CFG_MODUL_PROG_PRECOND_CFG_MODUL_PROG_PRECOND: accessed-variable=PRP_SR_CFG_MODUL_PROG_PRECOND.CFG_MODUL_PROG_PRECOND
            Dra_SR_CFG_PRESENCE_CIELO_CFG_PRESENCE_CIELO: accessed-variable=PRP_SR_CFG_PRESENCE_CIELO.CFG_PRESENCE_CIELO
            Dra_SR_CFG_MODUL_TAS_CFG_MODUL_TAS: accessed-variable=PRP_SR_CFG_MODUL_TAS.CFG_MODUL_TAS
            Dra_SR_CFG_MODUL_SOL_CFG_MODUL_SOL: accessed-variable=PRP_SR_CFG_MODUL_SOL.CFG_MODUL_SOL
            Dra_SR_CFG_MODUL_DCT_CFG_MODUL_DCT: accessed-variable=PRP_SR_CFG_MODUL_DCT.CFG_MODUL_DCT
            Dra_SR_CFG_TYPE_CLIM_CFG_TYPE_CLIM: accessed-variable=PRP_SR_CFG_TYPE_CLIM.CFG_TYPE_CLIM
            Dra_SR_CFG_TYPE_ARCHI_IHM_CLIM_CFG_TYPE_ARCHI_IHM_CLIM: accessed-variable=PRP_SR_CFG_TYPE_ARCHI_IHM_CLIM.CFG_TYPE_ARCHI_IHM_CLIM
            Dra_SR_CFG_TYPE_IHM_DISTRIB_AV_TACT_CFG_TYPE_IHM_DISTRIB_AV_TACT: accessed-variable=PRP_SR_CFG_TYPE_IHM_DISTRIB_AV_TACT.CFG_TYPE_IHM_DISTRIB_AV_TACT
            Dra_SR_CFG_TYPE_IHM_ENTREE_AIR_PHYS_CFG_TYPE_IHM_ENTREE_AIR_PHYS: accessed-variable=PRP_SR_CFG_TYPE_IHM_ENTREE_AIR_PHYS.CFG_TYPE_IHM_ENTREE_AIR_PHYS
            Dra_SR_CFG_TYPE_IHM_PULSEUR_AR_CFG_TYPE_IHM_PULSEUR_AR: accessed-variable=PRP_SR_CFG_TYPE_IHM_PULSEUR_AR.CFG_TYPE_IHM_PULSEUR_AR
            Dra_SR_CFG_TYPE_IHM_PULSEUR_AV_PHYS_CFG_TYPE_IHM_PULSEUR_AV_PHYS: accessed-variable=PRP_SR_CFG_TYPE_IHM_PULSEUR_AV_PHYS.CFG_TYPE_IHM_PULSEUR_AV_PHYS
            Dra_SR_CFG_TYPE_IHM_PULSEUR_AV_TACT_CFG_TYPE_IHM_PULSEUR_AV_TACT: accessed-variable=PRP_SR_CFG_TYPE_IHM_PULSEUR_AV_TACT.CFG_TYPE_IHM_PULSEUR_AV_TACT
            Dra_SR_CFG_TYPE_IHM_PULSEUR_RG3_CFG_TYPE_IHM_PULSEUR_RG3: accessed-variable=PRP_SR_CFG_TYPE_IHM_PULSEUR_RG3.CFG_TYPE_IHM_PULSEUR_RG3
            Dra_SR_CFG_TYPE_IHM_TEMP_AV_PHYS_CFG_TYPE_IHM_TEMP_AV_PHYS: accessed-variable=PRP_SR_CFG_TYPE_IHM_TEMP_AV_PHYS.CFG_TYPE_IHM_TEMP_AV_PHYS
            Dra_SR_CFG_TYPE_IHM_TEMP_AV_TACT_CFG_TYPE_IHM_TEMP_AV_TACT: accessed-variable=PRP_SR_CFG_TYPE_IHM_TEMP_AV_TACT.CFG_TYPE_IHM_TEMP_AV_TACT
            Dra_SR_CFG_TYPE_IHM_TYPAGE_AUTO_CFG_TYPE_IHM_TYPAGE_AUTO: accessed-variable=PRP_SR_CFG_TYPE_IHM_TYPAGE_AUTO.CFG_TYPE_IHM_TYPAGE_AUTO
            Dra_SR_CFG_TYPE_FAP_CFG_TYPE_FAP: accessed-variable=PRP_SR_CFG_TYPE_FAP.CFG_TYPE_FAP
            Dra_SR_CFG_NumTable_NH_CFG_NumTable_NH: accessed-variable=PRP_SR_CFG_NumTable_NH.CFG_NumTable_NH
            Dra_SR_CFG_ORIGINE_NHUILE_CFG_ORIGINE_NHUILE: accessed-variable=PRP_SR_CFG_ORIGINE_NHUILE.CFG_ORIGINE_NHUILE
            Dra_SR_CFG_PRESENCE_AUTO_INHIB_RBG_PASS_CFG_PRESENCE_AUTO_INHIB_RBG_PASS: accessed-variable=PRP_SR_CFG_PRESENCE_AUTO_INHIB_RBG_PASS.CFG_PRESENCE_AUTO_INHIB_RBG_PASS
            Dra_SR_CFG_PRESENCE_DSG_CFG_PRESENCE_DSG: accessed-variable=PRP_SR_CFG_PRESENCE_DSG.CFG_PRESENCE_DSG
            Dra_SR_CFG_TYPE_PUSH_DSGI_CFG_TYPE_PUSH_DSGI: accessed-variable=PRP_SR_CFG_TYPE_PUSH_DSGI.CFG_TYPE_PUSH_DSGI
            Dra_SR_CFG_PRESENCE_AVE_CFG_PRESENCE_AVE: accessed-variable=PRP_SR_CFG_PRESENCE_AVE.CFG_PRESENCE_AVE
            Dra_SR_CFG_TYPE_CHAINE_TRACTION_CFG_TYPE_CHAINE_TRACTION: accessed-variable=PRP_SR_CFG_TYPE_CHAINE_TRACTION.CFG_TYPE_CHAINE_TRACTION
            Dra_SR_CFG_TYPE_DEMARRAGE_CFG_TYPE_DEMARRAGE: accessed-variable=PRP_SR_CFG_TYPE_DEMARRAGE.CFG_TYPE_DEMARRAGE
            Dra_SR_CFG_TYPE_GMP_CFG_TYPE_GMP: accessed-variable=PRP_SR_CFG_TYPE_GMP.CFG_TYPE_GMP
            Dra_SR_CFG_PRESENCE_FARC_CFG_PRESENCE_FARC: accessed-variable=PRP_SR_CFG_PRESENCE_FARC.CFG_PRESENCE_FARC
            Dra_SR_CFG_PRESENCE_ARC_CFG_PRESENCE_ARC: accessed-variable=PRP_SR_CFG_PRESENCE_ARC.CFG_PRESENCE_ARC
            Dra_SR_CFG_AMVAR_CFG_AMVAR: accessed-variable=PRP_SR_CFG_AMVAR.CFG_AMVAR
            Dra_SR_TYPE_HMI_MODE_SELECTOR_TYPE_HMI_MODE_SELECTOR: accessed-variable=PRP_SR_TYPE_HMI_MODE_SELECTOR.TYPE_HMI_MODE_SELECTOR
            Dra_SR_CFG_PRESENCE_MODE_ECO_DYN_CFG_PRESENCE_MODE_ECO_DYN: accessed-variable=PRP_SR_CFG_PRESENCE_MODE_ECO_DYN.CFG_PRESENCE_MODE_ECO_DYN
            Dra_SR_CFG_PRESENCE_MEAP_CFG_PRESENCE_MEAP: accessed-variable=PRP_SR_CFG_PRESENCE_MEAP.CFG_PRESENCE_MEAP
            Dra_SR_CFG_POLYSENSORIAL_PACK_CFG_POLYSENSORIAL_PACK: accessed-variable=PRP_SR_CFG_POLYSENSORIAL_PACK.CFG_POLYSENSORIAL_PACK
            Dra_SR_CFG_PRESENCE_MODE_SPORT_DYN_CFG_PRESENCE_MODE_SPORT_DYN: accessed-variable=PRP_SR_CFG_PRESENCE_MODE_SPORT_DYN.CFG_PRESENCE_MODE_SPORT_DYN
            Dra_SR_CFG_OPTION_SONDE_EAU_GAZOLE_CFG_OPTION_SONDE_EAU_GAZOLE: accessed-variable=PRP_SR_CFG_OPTION_SONDE_EAU_GAZOLE.CFG_OPTION_SONDE_EAU_GAZOLE
            Dra_SR_CFG_TYPE_PACK_DYN_CFG_TYPE_PACK_DYN: accessed-variable=PRP_SR_CFG_TYPE_PACK_DYN.CFG_TYPE_PACK_DYN
            Dra_SR_CFG_AUTOR_MAP_HMI_CFG_AUTOR_MAP_HMI: accessed-variable=PRP_SR_CFG_AUTOR_MAP_HMI.CFG_AUTOR_MAP_HMI
            Dra_SR_CFG_FCT_GSI_CFG_FCT_GSI: accessed-variable=PRP_SR_CFG_FCT_GSI.CFG_FCT_GSI
            Dra_SR_CFG_TYPE_BOITE_CFG_TYPE_BOITE: accessed-variable=PRP_SR_CFG_TYPE_BOITE.CFG_TYPE_BOITE
            Dra_SR_CFG_TYPE_SC_CFG_TYPE_SC: accessed-variable=PRP_SR_CFG_TYPE_SC.CFG_TYPE_SC
            Dra_SR_CFG_ACQ_PUSH_ESP_CFG_ACQ_PUSH_ESP: accessed-variable=PRP_SR_CFG_ACQ_PUSH_ESP.CFG_ACQ_PUSH_ESP
            Dra_SR_CFG_PRESENCE_ASR_PLUS_CFG_PRESENCE_ASR_PLUS: accessed-variable=PRP_SR_CFG_PRESENCE_ASR_PLUS.CFG_PRESENCE_ASR_PLUS
            Dra_SR_CFG_OPTION_HBB_HBC_CFG_OPTION_HBB_HBC: accessed-variable=PRP_SR_CFG_OPTION_HBB_HBC.CFG_OPTION_HBB_HBC
            Dra_SR_CFG_OPTION_PLV_CFG_OPTION_PLV: accessed-variable=PRP_SR_CFG_OPTION_PLV.CFG_OPTION_PLV
            Dra_SR_CFG_PRESENCE_LVVRVV_CFG_PRESENCE_LVVRVV: accessed-variable=PRP_SR_CFG_PRESENCE_LVVRVV.CFG_PRESENCE_LVVRVV
            Dra_SR_CFG_TYPE_ACC_CFG_TYPE_ACC: accessed-variable=PRP_SR_CFG_TYPE_ACC.CFG_TYPE_ACC
            Dra_SR_CFG_TYPE_TARGET_DETECTION_CFG_TYPE_TARGET_DETECTION: accessed-variable=PRP_SR_CFG_TYPE_TARGET_DETECTION.CFG_TYPE_TARGET_DETECTION
            Dra_SR_CFG_TYPE_AQUI_PUSH_STT_CFG_TYPE_AQUI_PUSH_STT: accessed-variable=PRP_SR_CFG_TYPE_AQUI_PUSH_STT.CFG_TYPE_AQUI_PUSH_STT
            Dra_SR_CFG_TYPE_STT_CFG_TYPE_STT: accessed-variable=PRP_SR_CFG_TYPE_STT.CFG_TYPE_STT
            Dra_SR_CFG_TypeCPK_CFG_TypeCPK: accessed-variable=PRP_SR_CFG_TypeCPK.CFG_TypeCPK
            Dra_SR_CFG_OPTION_SAM_CFG_OPTION_SAM: accessed-variable=PRP_SR_CFG_OPTION_SAM.CFG_OPTION_SAM
            Dra_SR_CFG_PRESENCE_PUSH_SAM_CFG_PRESENCE_PUSH_SAM: accessed-variable=PRP_SR_CFG_PRESENCE_PUSH_SAM.CFG_PRESENCE_PUSH_SAM
            Dra_SR_CFG_OPTION_DOP_CFG_OPTION_DOP: accessed-variable=PRP_SR_CFG_OPTION_DOP.CFG_OPTION_DOP
            Dra_SR_CFG_PRESENCE_ECOACH_CFG_PRESENCE_ECOACH: accessed-variable=PRP_SR_CFG_PRESENCE_ECOACH.CFG_PRESENCE_ECOACH
            Dra_SR_CFG_NIV_ALERTE_MINI_CARB_CFG_NIV_ALERTE_MINI_CARB: accessed-variable=PRP_SR_CFG_NIV_ALERTE_MINI_CARB.CFG_NIV_ALERTE_MINI_CARB
            Dra_SR_C7D_NIV_CARB_CRITIQUE_C7D_NIV_CARB_CRITIQUE: accessed-variable=PRP_SR_C7D_NIV_CARB_CRITIQUE.C7D_NIV_CARB_CRITIQUE
            Dra_SR_CFG_NUM_TABLE_CARB_CFG_NUM_TABLE_CARB: accessed-variable=PRP_SR_CFG_NUM_TABLE_CARB.CFG_NUM_TABLE_CARB
            Dra_SR_CfgTypeLocksSteering_CfgTypeLocksSteering: accessed-variable=PRP_SR_CfgTypeLocksSteering.CfgTypeLocksSteering
            Dra_SR_CFG_OPTION_BLUETOOTH_CFG_OPTION_BLUETOOTH: accessed-variable=PRP_SR_CFG_OPTION_BLUETOOTH.CFG_OPTION_BLUETOOTH
            Dra_SR_CFG_OPTION_BAA_CFG_OPTION_BAA: accessed-variable=PRP_SR_CFG_OPTION_BAA.CFG_OPTION_BAA
            Dra_SR_CfgTypeTrunkPushInterior_CfgTypeTrunkPushInterior: accessed-variable=PRP_SR_CfgTypeTrunkPushInterior.CfgTypeTrunkPushInterior
            Dra_SR_CfgTypeRearOpening_CfgTypeRearOpening: accessed-variable=PRP_SR_CfgTypeRearOpening.CfgTypeRearOpening
            Dra_SR_CFG_VOLET_MOTORISE_CFG_VOLET_MOTORISE: accessed-variable=PRP_SR_CFG_VOLET_MOTORISE.CFG_VOLET_MOTORISE
            Dra_SR_CfgSelectivityDoors_CfgSelectivityDoors: accessed-variable=PRP_SR_CfgSelectivityDoors.CfgSelectivityDoors
            Dra_SR_CFG_STEERING_WHEEL_POSITION_CFG_STEERING_WHEEL_POSITION: accessed-variable=PRP_SR_CFG_STEERING_WHEEL_POSITION.CFG_STEERING_WHEEL_POSITION
            Dra_SR_CFG_CONDA_CFG_CONDA: accessed-variable=PRP_SR_CFG_CONDA.CFG_CONDA
            Dra_SR_CFG_PLIP_TOUCH_3_FUNCTION_CFG_PLIP_TOUCH_3_FUNCTION: accessed-variable=PRP_SR_CFG_PLIP_TOUCH_3_FUNCTION.CFG_PLIP_TOUCH_3_FUNCTION
            Dra_SR_CFG_PLIP_WL_FUNCTIONNALITY_CFG_PLIP_WL_FUNCTIONNALITY: accessed-variable=PRP_SR_CFG_PLIP_WL_FUNCTIONNALITY.CFG_PLIP_WL_FUNCTIONNALITY
            Dra_SR_CFG_PLIP_WL_BEHAVIOR_CFG_PLIP_WL_BEHAVIOR: accessed-variable=PRP_SR_CFG_PLIP_WL_BEHAVIOR.CFG_PLIP_WL_BEHAVIOR
            Dra_SR_CFG_PLIP_PRESS_TYPE_TOUCH_3_CFG_PLIP_PRESS_TYPE_TOUCH_3: accessed-variable=PRP_SR_CFG_PLIP_PRESS_TYPE_TOUCH_3.CFG_PLIP_PRESS_TYPE_TOUCH_3
            Dra_SR_CFG_DRIVER_LOCK_TYPE_CFG_DRIVER_LOCK_TYPE: accessed-variable=PRP_SR_CFG_DRIVER_LOCK_TYPE.CFG_DRIVER_LOCK_TYPE
            Dra_SR_CFG_FUEL_FLAP_LOCK_TYPE_CFG_FUEL_FLAP_LOCK_TYPE: accessed-variable=PRP_SR_CFG_FUEL_FLAP_LOCK_TYPE.CFG_FUEL_FLAP_LOCK_TYPE
            Dra_SR_CFG_HOOD_LOCK_TYPE_CFG_HOOD_LOCK_TYPE: accessed-variable=PRP_SR_CFG_HOOD_LOCK_TYPE.CFG_HOOD_LOCK_TYPE
            Dra_SR_CFG_REAR_LEFT_LOCK_TYPE_CFG_REAR_LEFT_LOCK_TYPE: accessed-variable=PRP_SR_CFG_REAR_LEFT_LOCK_TYPE.CFG_REAR_LEFT_LOCK_TYPE
            Dra_SR_CFG_REAR_RIGHT_LOCK_TYPE_CFG_REAR_RIGHT_LOCK_TYPE: accessed-variable=PRP_SR_CFG_REAR_RIGHT_LOCK_TYPE.CFG_REAR_RIGHT_LOCK_TYPE
            Dra_SR_CFG_OPTION_SUNROOF_CFG_OPTION_SUNROOF: accessed-variable=PRP_SR_CFG_OPTION_SUNROOF.CFG_OPTION_SUNROOF
            Dra_SR_CfgRearViewMirrorIndexingReverseGear_CfgRearViewMirrorIndexingReverseGear: accessed-variable=PRP_SR_CfgRearViewMirrorIndexingReverseGear.CfgRearViewMirrorIndexingReverseGear
            Dra_SR_CFG_OPTION_SIEGE_CLIM_CFG_OPTION_SIEGE_CLIM: accessed-variable=PRP_SR_CFG_OPTION_SIEGE_CLIM.CFG_OPTION_SIEGE_CLIM
            Dra_SR_CFG_PRES_VOLANT_CHAUF_CFG_PRES_VOLANT_CHAUF: accessed-variable=PRP_SR_CFG_PRES_VOLANT_CHAUF.CFG_PRES_VOLANT_CHAUF
            Dra_SR_CFG_TYPE_SOC_CFG_TYPE_SOC: accessed-variable=PRP_SR_CFG_TYPE_SOC.CFG_TYPE_SOC
            Dra_SR_CFG_OPTION_VISION_NOCTURNE_CFG_OPTION_VISION_NOCTURNE: accessed-variable=PRP_SR_CFG_OPTION_VISION_NOCTURNE.CFG_OPTION_VISION_NOCTURNE
            Dra_SR_CFG_AUTOR_MAP_ECLI_CFG_AUTOR_MAP_ECLI: accessed-variable=PRP_SR_CFG_AUTOR_MAP_ECLI.CFG_AUTOR_MAP_ECLI
            Dra_SR_CFG_POLYCHROME_AMB_CFG_POLYCHROME_AMB: accessed-variable=PRP_SR_CFG_POLYCHROME_AMB.CFG_POLYCHROME_AMB
            Dra_SR_CFG_OPTION_AFS_CFG_OPTION_AFS: accessed-variable=PRP_SR_CFG_OPTION_AFS.CFG_OPTION_AFS
            Dra_SR_CFG_OPTION_ECL_INTERSEC_CFG_OPTION_ECL_INTERSEC: accessed-variable=PRP_SR_CFG_OPTION_ECL_INTERSEC.CFG_OPTION_ECL_INTERSEC
            Dra_SR_CFG_OPTION_ECL_VIR_STAT_CFG_OPTION_ECL_VIR_STAT: accessed-variable=PRP_SR_CFG_OPTION_ECL_VIR_STAT.CFG_OPTION_ECL_VIR_STAT
            Dra_SR_CFG_OPTION_ANTIBR_AV_CFG_OPTION_ANTIBR_AV: accessed-variable=PRP_SR_CFG_OPTION_ANTIBR_AV.CFG_OPTION_ANTIBR_AV
            Dra_SR_CFG_TypeEclairageAV_CFG_TypeEclairageAV: accessed-variable=PRP_SR_CFG_TypeEclairageAV.CFG_TypeEclairageAV
            Dra_SR_CFG_PRESENCE_BSG_RQ_CFG_PRESENCE_BSG_RQ: accessed-variable=PRP_SR_CFG_PRESENCE_BSG_RQ.CFG_PRESENCE_BSG_RQ
            Dra_SR_CFG_INHIB_MOVING_EFFECT_CFG_INHIB_MOVING_EFFECT: accessed-variable=PRP_SR_CFG_INHIB_MOVING_EFFECT.CFG_INHIB_MOVING_EFFECT
            Dra_SR_CFG_FONCTION_AHB_CFG_FONCTION_AHB: accessed-variable=PRP_SR_CFG_FONCTION_AHB.CFG_FONCTION_AHB
            Dra_SR_CFG_OPTION_AAF_CFG_OPTION_AAF: accessed-variable=PRP_SR_CFG_OPTION_AAF.CFG_OPTION_AAF
            Dra_SR_CFG_TYPE_COMODO_CFG_TYPE_COMODO: accessed-variable=PRP_SR_CFG_TYPE_COMODO.CFG_TYPE_COMODO
            Dra_SR_CFG_Barrette_TNB_sur_LIN_CFG_Barrette_TNB_sur_LIN: accessed-variable=PRP_SR_CFG_Barrette_TNB_sur_LIN.CFG_Barrette_TNB_sur_LIN
            Dra_SR_CFG_INHIB_DIAG_TNB_COND_CFG_INHIB_DIAG_TNB_COND: accessed-variable=PRP_SR_CFG_INHIB_DIAG_TNB_COND.CFG_INHIB_DIAG_TNB_COND
            Dra_SR_CFG_INHIB_DIAG_TNB_PAR2C_CFG_INHIB_DIAG_TNB_PAR2C: accessed-variable=PRP_SR_CFG_INHIB_DIAG_TNB_PAR2C.CFG_INHIB_DIAG_TNB_PAR2C
            Dra_SR_CFG_INHIB_DIAG_TNB_PAR2D_CFG_INHIB_DIAG_TNB_PAR2D: accessed-variable=PRP_SR_CFG_INHIB_DIAG_TNB_PAR2D.CFG_INHIB_DIAG_TNB_PAR2D
            Dra_SR_CFG_INHIB_DIAG_TNB_PAR2G_CFG_INHIB_DIAG_TNB_PAR2G: accessed-variable=PRP_SR_CFG_INHIB_DIAG_TNB_PAR2G.CFG_INHIB_DIAG_TNB_PAR2G
            Dra_SR_CFG_OPTION_TAXI_CFG_OPTION_TAXI: accessed-variable=PRP_SR_CFG_OPTION_TAXI.CFG_OPTION_TAXI
            Dra_SR_CFG_INHIB_DIAG_TNB_PAV_CFG_INHIB_DIAG_TNB_PAV: accessed-variable=PRP_SR_CFG_INHIB_DIAG_TNB_PAV.CFG_INHIB_DIAG_TNB_PAV
            Dra_SR_CFG_NAPPE_DETECTION_PASS_CFG_NAPPE_DETECTION_PASS: accessed-variable=PRP_SR_CFG_NAPPE_DETECTION_PASS.CFG_NAPPE_DETECTION_PASS
            Dra_SR_CFG_NBR_CNB_CFG_NBR_CNB: accessed-variable=PRP_SR_CFG_NBR_CNB.CFG_NBR_CNB
            Dra_SR_CFG_TYPE_PRES_PASS_SENSOR_CFG_TYPE_PRES_PASS_SENSOR: accessed-variable=PRP_SR_CFG_TYPE_PRES_PASS_SENSOR.CFG_TYPE_PRES_PASS_SENSOR
            Dra_SR_CFG_PRESENCE_OPTION_MEMORISATION_CFG_PRESENCE_OPTION_MEMORISATION: accessed-variable=PRP_SR_CFG_PRESENCE_OPTION_MEMORISATION.CFG_PRESENCE_OPTION_MEMORISATION
            Dra_SR_CFG_WELCOME_DRIVER_SEAT_FUNCTION_CFG_WELCOME_DRIVER_SEAT_FUNCTION: accessed-variable=PRP_SR_CFG_WELCOME_DRIVER_SEAT_FUNCTION.CFG_WELCOME_DRIVER_SEAT_FUNCTION
            Dra_SR_CFG_OPTION_MASSAGE_CFG_OPTION_MASSAGE: accessed-variable=PRP_SR_CFG_OPTION_MASSAGE.CFG_OPTION_MASSAGE
            Dra_SR_CFG_PRESENCE_VTH_CFG_PRESENCE_VTH: accessed-variable=PRP_SR_CFG_PRESENCE_VTH.CFG_PRESENCE_VTH
            Dra_SR_CFG_MEMO_REGL_RETROS_CFG_MEMO_REGL_RETROS: accessed-variable=PRP_SR_CFG_MEMO_REGL_RETROS.CFG_MEMO_REGL_RETROS
            Dra_SR_CFG_PRESENCE_PBC_CFG_PRESENCE_PBC: accessed-variable=PRP_SR_CFG_PRESENCE_PBC.CFG_PRESENCE_PBC
            Dra_SR_CFG_CLIMAT_CFG_CLIMAT: accessed-variable=PRP_SR_CFG_CLIMAT.CFG_CLIMAT
            Dra_SR_CfgTypeFrontDefrost_CfgTypeFrontDefrost: accessed-variable=PRP_SR_CfgTypeFrontDefrost.CfgTypeFrontDefrost
            Dra_SR_CFG_TYPE_MODUL_OPTI_VIDE_CFG_TYPE_MODUL_OPTI_VIDE: accessed-variable=PRP_SR_CFG_TYPE_MODUL_OPTI_VIDE.CFG_TYPE_MODUL_OPTI_VIDE
            Dra_SR_CfgSweepingCourtesy_CfgSweepingCourtesy: accessed-variable=PRP_SR_CfgSweepingCourtesy.CfgSweepingCourtesy
            Dra_SR_CfgRainSensor_CfgRainSensor: accessed-variable=PRP_SR_CfgRainSensor.CfgRainSensor
            Dra_SR_SCR_AFFICH_POI_ADBLUE_SCR_AFFICH_POI_ADBLUE: accessed-variable=PRP_SR_SCR_AFFICH_POI_ADBLUE.SCR_AFFICH_POI_ADBLUE
            Dra_SR_CFG_PRESENCE_SCR_CFG_PRESENCE_SCR: accessed-variable=PRP_SR_CFG_PRESENCE_SCR.CFG_PRESENCE_SCR
            Dra_SR_CFG_DISPO_PSEUDO_CONSO_CARB_CFG_DISPO_PSEUDO_CONSO_CARB: accessed-variable=PRP_SR_CFG_DISPO_PSEUDO_CONSO_CARB.CFG_DISPO_PSEUDO_CONSO_CARB
            Dra_SR_CFG_EngineMaintType_CFG_EngineMaintType: accessed-variable=PRP_SR_CFG_EngineMaintType.CFG_EngineMaintType
            Dra_SR_M230_TimeFirstMaint_M230_TimeFirstMaint: accessed-variable=PRP_SR_M230_TimeFirstMaint.M230_TimeFirstMaint
            Dra_SR_M230_TimeOtherMaint_M230_TimeOtherMaint: accessed-variable=PRP_SR_M230_TimeOtherMaint.M230_TimeOtherMaint
            Dra_SR_M230_KmFirstMaint_M230_KmFirstMaint: accessed-variable=PRP_SR_M230_KmFirstMaint.M230_KmFirstMaint
            Dra_SR_M230_KmOtherMaint_M230_KmOtherMaint: accessed-variable=PRP_SR_M230_KmOtherMaint.M230_KmOtherMaint
            Dra_SR_M230_KmOrTimeMaint_M230_KmOrTimeMaint: accessed-variable=PRP_SR_M230_KmOrTimeMaint.M230_KmOrTimeMaint
            Dra_SR_CFG_DISTRACTION_MODE_CFG_DISTRACTION_MODE: accessed-variable=PRP_SR_CFG_DISTRACTION_MODE.CFG_DISTRACTION_MODE
            Dra_SR_CFG_PresenceCRT_CFG_PresenceCRT: accessed-variable=PRP_SR_CFG_PresenceCRT.CFG_PresenceCRT
            Dra_SR_CFG_TYPE_BTEL_CFG_TYPE_BTEL: accessed-variable=PRP_SR_CFG_TYPE_BTEL.CFG_TYPE_BTEL
            Dra_SR_CFG_SOFTWARE_UPDATE_CAPABILITY_CFG_SOFTWARE_UPDATE_CAPABILITY: accessed-variable=PRP_SR_CFG_SOFTWARE_UPDATE_CAPABILITY.CFG_SOFTWARE_UPDATE_CAPABILITY
            Dra_SR_DiagCodeVIN_DiagCodeVIN_{01..17}: accessed-variable=PRP_SR_DiagCodeVIN.DiagCodeVIN_{01..17}
            Dra_SR_CFG_SMARTDEVICE_BY_SDCM_CFG_SMARTDEVICE_BY_SDCM: accessed-variable=PRP_SR_CFG_SMARTDEVICE_BY_SDCM.CFG_SMARTDEVICE_BY_SDCM
            Dra_SR_CFG_AUTOR_MAP_INVIO_CFG_AUTOR_MAP_INVIO: accessed-variable=PRP_SR_CFG_AUTOR_MAP_INVIO.CFG_AUTOR_MAP_INVIO
            Dra_SR_CFG_GEN_RSK16_CFG_GEN_RSK16: accessed-variable=PRP_SR_CFG_GEN_RSK16.CFG_GEN_RSK16
            Dra_SR_CFG_OPTION_WLC_CFG_OPTION_WLC: accessed-variable=PRP_SR_CFG_OPTION_WLC.CFG_OPTION_WLC
            Dra_SR_CFG_TYPE_CLE_CFG_TYPE_CLE: accessed-variable=PRP_SR_CFG_TYPE_CLE.CFG_TYPE_CLE
            Dra_SR_CFG_ALARME_2NDE_MONTE_CFG_ALARME_2NDE_MONTE: accessed-variable=PRP_SR_CFG_ALARME_2NDE_MONTE.CFG_ALARME_2NDE_MONTE
            Dra_SR_CFG_INHIB_VOLUMETRIE_CFG_INHIB_VOLUMETRIE: accessed-variable=PRP_SR_CFG_INHIB_VOLUMETRIE.CFG_INHIB_VOLUMETRIE
            Dra_SR_CFG_PRESENCE_MUS_LIN_CFG_PRESENCE_MUS_LIN: accessed-variable=PRP_SR_CFG_PRESENCE_MUS_LIN.CFG_PRESENCE_MUS_LIN
            Dra_SR_CFG_PRESENCE_SIRENE_LIN_CFG_PRESENCE_SIRENE_LIN: accessed-variable=PRP_SR_CFG_PRESENCE_SIRENE_LIN.CFG_PRESENCE_SIRENE_LIN
            Dra_SR_CFG_TYPE_ALARME_CFG_TYPE_ALARME: accessed-variable=PRP_SR_CFG_TYPE_ALARME.CFG_TYPE_ALARME
            Dra_SR_CFG_OPTIONS_TLM_CFG_OPTIONS_TLM: accessed-variable=PRP_SR_CFG_OPTIONS_TLM.CFG_OPTIONS_TLM
            Dra_SR_CFG_PROCESS_USINE_{01..06}_CFG_PROCESS_USINE_{01..06}: accessed-variable=PRP_SR_CFG_PROCESS_USINE_{01..06}.CFG_PROCESS_USINE_{01..06}
            Dra_SR_CFG_DATE_TELECODAGE_{1..3}_CFG_DATE_TELECODAGE_{1..3}: accessed-variable=PRP_SR_CFG_DATE_TELECODAGE_{1..3}.CFG_DATE_TELECODAGE_{1..3}
            Dra_SR_CFG_SIGNATURE_OUTIL_{1..3}_CFG_SIGNATURE_OUTIL_{1..3}: accessed-variable=PRP_SR_CFG_SIGNATURE_OUTIL_{1..3}.CFG_SIGNATURE_OUTIL_{1..3}
            Dra_SR_CFG_SITE_TELECODAGE_CFG_SITE_TELECODAGE: accessed-variable=PRP_SR_CFG_SITE_TELECODAGE.CFG_SITE_TELECODAGE
            Dra_SR_CFG_UCE_{001..026}_CFG_UCE_{001..026}: accessed-variable=PRP_SR_CFG_UCE_{001..026}.CFG_UCE_{001..026}
            Dra_SR_CFG_UCE_{028..069}_CFG_UCE_{028..069}: accessed-variable=PRP_SR_CFG_UCE_{028..069}.CFG_UCE_{028..069}
package /RootP_Implementation
  swc implementation Implementation_Aswc_IntDcm: programming-language=C, sw-version=1.0.0, vendor-id=1, behavior=IB_Aswc_IntDcm
    code-descriptors:
      code SRC: artifact-descriptors=autosar-engineering-object={short-label=EngObject, category=SWSRC}
    resource consumption Resources
      memory section CODE: sw-addrmethod=CODE_Aswc_IntDcm
  sw addr method CODE_Aswc_IntDcm: memory-allocation-keyword-policy=ADDR-METHOD-SHORT-NAME-AND-ALIGNMENT, section-type=CODE
